VERSION ""

NS_ :

BS_:

BU_: Tester EMS
VAL_TABLE_ FMI 31 "Not available" 19 "Received network data in error" 18 "Below normal (moderately severe)" 17 "Below normal (least severe)" 16 "Above normal (moderately severe)" 15 "Above normal (least severe)" 14 "Special intstructions" 13 "Out of calibration" 12 "Bad intelligent device" 11 "Root cause not known" 10 "Abnormal rate of change" 9 "Abnormal update rate" 8 "Abnormal frequency" 7 "Mechanical system not responding" 6 "Current above normal" 5 "Current below normal" 4 "Voltage below normal" 3 "Voltage above normal" 2 "Data erratic" 1 "Below normal (most severe)" 0 "Above normal (most severe)" ;

BO_ 3221225472 VECTOR__INDEPENDENT_SIG_MSG: 0 Vector__XXX
 SG_ SPN5 : 0|16@1+ (1,0) [0|65536] "" Vector__XXX
 SG_ SPN4 : 0|16@1+ (1,0) [0|65536] "" Vector__XXX
 SG_ SPN3 : 0|16@1+ (1,0) [0|65536] "" Vector__XXX
 SG_ SPN2 : 0|16@1+ (1,0) [0|65536] "" Vector__XXX
 SG_ FailureModeIdentifier5 : 0|5@1+ (1,0) [0|0] "" Vector__XXX
 SG_ FailureModeIdentifier4 : 0|5@1+ (1,0) [0|0] "" Vector__XXX
 SG_ FlashRedStopLamp : 0|2@1+ (1,0) [0|3] "" Vector__XXX
 SG_ FlashProtectLamp : 0|2@1+ (1,0) [0|3] "" Vector__XXX
 SG_ FlashMalfuncIndicatorLamp : 0|2@1+ (1,0) [0|3] "" Vector__XXX
 SG_ FlashAmberWarningLamp : 0|2@1+ (1,0) [0|3] "" Vector__XXX
 SG_ FailureModeIdentifier3 : 0|5@1+ (1,0) [0|0] "" Vector__XXX
 SG_ FailureModeIdentifier2 : 0|5@1+ (1,0) [0|0] "" Vector__XXX
 SG_ SPNConversionMethod5 : 0|1@1+ (1,0) [0|1] "" Vector__XXX
 SG_ SPNConversionMethod4 : 0|1@1+ (1,0) [0|1] "" Vector__XXX
 SG_ SPNConversionMethod3 : 0|1@1+ (1,0) [0|1] "" Vector__XXX
 SG_ SPNConversionMethod2 : 0|1@1+ (1,0) [0|1] "" Vector__XXX
 SG_ OccurenceCount5 : 0|7@1+ (1,0) [0|126] "" Vector__XXX
 SG_ OccurenceCount4 : 0|7@1+ (1,0) [0|126] "" Vector__XXX
 SG_ OccurenceCount3 : 0|7@1+ (1,0) [0|126] "" Vector__XXX
 SG_ OccurenceCount2 : 0|7@1+ (1,0) [0|126] "" Vector__XXX
 SG_ OccurenceCount1 : 0|7@1+ (1,0) [0|126] "" Vector__XXX
 SG_ SPNConversionMethod1 : 0|1@1+ (1,0) [0|1] "" Vector__XXX
 SG_ FailureModeIdentifier1 : 0|5@1+ (1,0) [0|0] "" Vector__XXX
 SG_ SPN1 : 0|16@1+ (1,0) [0|65536] "" Vector__XXX
 SG_ MalfunctionIndicatorLampStatus : 0|2@1+ (1,0) [0|3] "" Vector__XXX
 SG_ RedStopLampState : 0|2@1+ (1,0) [0|3] "" Vector__XXX
 SG_ AmberWarningLampStatus : 0|2@1+ (1,0) [0|3] "" Vector__XXX
 SG_ ProtectLampStatus : 0|2@1+ (1,0) [0|3] "" Vector__XXX
 SG_ SPN5High : 0|3@1+ (1,0) [0|7] "" Vector__XXX
 SG_ SPN4High : 0|3@1+ (1,0) [0|7] "" Vector__XXX
 SG_ SPN3High : 0|3@1+ (1,0) [0|7] "" Vector__XXX
 SG_ SPN2High : 0|3@1+ (1,0) [0|7] "" Vector__XXX
 SG_ SPN1High : 0|3@1+ (1,0) [0|7] "" Vector__XXX
 SG_ OccurenceCount1 : 0|7@1+ (1,0) [0|126] "" Vector__XXX
 SG_ SPNConversionMethod1 : 0|1@1+ (1,0) [0|1] "" Vector__XXX
 SG_ FailureModeIdentifier1 : 0|5@1+ (1,0) [0|0] "" Vector__XXX
 SG_ SPN1 : 0|16@1+ (1,0) [0|65536] "" Vector__XXX
 SG_ SPN1High : 0|3@1+ (1,0) [0|7] "" Vector__XXX
 SG_ OccurenceCount1 : 0|7@1+ (1,0) [0|126] "" Vector__XXX
 SG_ SPNConversionMethod1 : 0|1@1+ (1,0) [0|1] "" Vector__XXX
 SG_ FailureModeIdentifier1 : 0|5@1+ (1,0) [0|0] "" Vector__XXX
 SG_ SPN1 : 0|16@1+ (1,0) [0|65536] "" Vector__XXX
 SG_ SPN1High : 0|3@1+ (1,0) [0|7] "" Vector__XXX
 SG_ SPN5 : 0|16@1+ (1,0) [0|65536] "" Vector__XXX
 SG_ SPN4 : 0|16@1+ (1,0) [0|65536] "" Vector__XXX
 SG_ SPN3 : 0|16@1+ (1,0) [0|65536] "" Vector__XXX
 SG_ SPN2 : 0|16@1+ (1,0) [0|65536] "" Vector__XXX
 SG_ FailureModeIdentifier5 : 0|5@1+ (1,0) [0|0] "" Vector__XXX
 SG_ FailureModeIdentifier4 : 0|5@1+ (1,0) [0|0] "" Vector__XXX
 SG_ OccurenceCount1 : 0|7@1+ (1,0) [0|126] "" Vector__XXX
 SG_ SPNConversionMethod1 : 0|1@1+ (1,0) [0|1] "" Vector__XXX
 SG_ FailureModeIdentifier1 : 0|5@1+ (1,0) [0|0] "" Vector__XXX
 SG_ SPN1 : 0|16@1+ (1,0) [0|65536] "" Vector__XXX
 SG_ MalfunctionIndicatorLampStatus : 0|2@1+ (1,0) [0|3] "" Vector__XXX
 SG_ RedStopLampState : 0|2@1+ (1,0) [0|3] "" Vector__XXX
 SG_ AmberWarningLampStatus : 0|2@1+ (1,0) [0|3] "" Vector__XXX
 SG_ ProtectLampStatus : 0|2@1+ (1,0) [0|3] "" Vector__XXX
 SG_ FailureModeIdentifier3 : 0|5@1+ (1,0) [0|0] "" Vector__XXX
 SG_ FlashRedStopLamp : 0|2@1+ (1,0) [0|3] "" Vector__XXX
 SG_ FlashProtectLamp : 0|2@1+ (1,0) [0|3] "" Vector__XXX
 SG_ FlashMalfuncIndicatorLamp : 0|2@1+ (1,0) [0|3] "" Vector__XXX
 SG_ FlashAmberWarningLamp : 0|2@1+ (1,0) [0|3] "" Vector__XXX
 SG_ FailureModeIdentifier2 : 0|5@1+ (1,0) [0|0] "" Vector__XXX
 SG_ SPNConversionMethod5 : 0|1@1+ (1,0) [0|1] "" Vector__XXX
 SG_ SPNConversionMethod4 : 0|1@1+ (1,0) [0|1] "" Vector__XXX
 SG_ SPNConversionMethod3 : 0|1@1+ (1,0) [0|1] "" Vector__XXX
 SG_ SPNConversionMethod2 : 0|1@1+ (1,0) [0|1] "" Vector__XXX
 SG_ OccurenceCount5 : 0|7@1+ (1,0) [0|126] "" Vector__XXX
 SG_ OccurenceCount4 : 0|7@1+ (1,0) [0|126] "" Vector__XXX
 SG_ OccurenceCount3 : 0|7@1+ (1,0) [0|126] "" Vector__XXX
 SG_ OccurenceCount2 : 0|7@1+ (1,0) [0|126] "" Vector__XXX
 SG_ SPN5High : 0|3@1+ (1,0) [0|7] "" Vector__XXX
 SG_ SPN4High : 0|3@1+ (1,0) [0|7] "" Vector__XXX
 SG_ SPN3High : 0|3@1+ (1,0) [0|7] "" Vector__XXX
 SG_ SPN2High : 0|3@1+ (1,0) [0|7] "" Vector__XXX
 SG_ SPN1High : 0|3@1+ (1,0) [0|7] "" Vector__XXX
 SG_ SPN5 : 0|16@1+ (1,0) [0|65536] "" Vector__XXX
 SG_ SPN4 : 0|16@1+ (1,0) [0|65536] "" Vector__XXX
 SG_ SPN3 : 0|16@1+ (1,0) [0|65536] "" Vector__XXX
 SG_ SPN2 : 0|16@1+ (1,0) [0|65536] "" Vector__XXX
 SG_ FlashRedStopLamp : 0|2@1+ (1,0) [0|3] "" Vector__XXX
 SG_ FlashProtectLamp : 0|2@1+ (1,0) [0|3] "" Vector__XXX
 SG_ FailureModeIdentifier5 : 0|5@1+ (1,0) [0|0] "" Vector__XXX
 SG_ FailureModeIdentifier4 : 0|5@1+ (1,0) [0|0] "" Vector__XXX
 SG_ FailureModeIdentifier3 : 0|5@1+ (1,0) [0|0] "" Vector__XXX
 SG_ OccurenceCount1 : 0|7@1+ (1,0) [0|126] "" Vector__XXX
 SG_ SPNConversionMethod1 : 0|1@1+ (1,0) [0|1] "" Vector__XXX
 SG_ FailureModeIdentifier1 : 0|5@1+ (1,0) [0|0] "" Vector__XXX
 SG_ SPN1 : 0|16@1+ (1,0) [0|65536] "" Vector__XXX
 SG_ MalfunctionIndicatorLampStatus : 0|2@1+ (1,0) [0|3] "" Vector__XXX
 SG_ RedStopLampState : 0|2@1+ (1,0) [0|3] "" Vector__XXX
 SG_ AmberWarningLampStatus : 0|2@1+ (1,0) [0|3] "" Vector__XXX
 SG_ ProtectLampStatus : 0|2@1+ (1,0) [0|3] "" Vector__XXX
 SG_ FlashMalfuncIndicatorLamp : 0|2@1+ (1,0) [0|3] "" Vector__XXX
 SG_ FlashAmberWarningLamp : 0|2@1+ (1,0) [0|3] "" Vector__XXX
 SG_ FailureModeIdentifier2 : 0|5@1+ (1,0) [0|0] "" Vector__XXX
 SG_ SPNConversionMethod5 : 0|1@1+ (1,0) [0|1] "" Vector__XXX
 SG_ SPNConversionMethod4 : 0|1@1+ (1,0) [0|1] "" Vector__XXX
 SG_ SPNConversionMethod3 : 0|1@1+ (1,0) [0|1] "" Vector__XXX
 SG_ SPNConversionMethod2 : 0|1@1+ (1,0) [0|1] "" Vector__XXX
 SG_ OccurenceCount5 : 0|7@1+ (1,0) [0|126] "" Vector__XXX
 SG_ OccurenceCount4 : 0|7@1+ (1,0) [0|126] "" Vector__XXX
 SG_ OccurenceCount3 : 0|7@1+ (1,0) [0|126] "" Vector__XXX
 SG_ OccurenceCount2 : 0|7@1+ (1,0) [0|126] "" Vector__XXX
 SG_ SPN5High : 0|3@1+ (1,0) [0|7] "" Vector__XXX
 SG_ SPN4High : 0|3@1+ (1,0) [0|7] "" Vector__XXX
 SG_ SPN3High : 0|3@1+ (1,0) [0|7] "" Vector__XXX
 SG_ SPN2High : 0|3@1+ (1,0) [0|7] "" Vector__XXX
 SG_ SPN1High : 0|3@1+ (1,0) [0|7] "" Vector__XXX
 SG_ SPN5 : 0|16@1+ (1,0) [0|65536] "" Vector__XXX
 SG_ SPN4 : 0|16@1+ (1,0) [0|65536] "" Vector__XXX
 SG_ SPN3 : 0|16@1+ (1,0) [0|65536] "" Vector__XXX
 SG_ SPN2 : 0|16@1+ (1,0) [0|65536] "" Vector__XXX
 SG_ FailureModeIdentifier5 : 0|5@1+ (1,0) [0|0] "" Vector__XXX
 SG_ FailureModeIdentifier4 : 0|5@1+ (1,0) [0|0] "" Vector__XXX
 SG_ FailureModeIdentifier3 : 0|5@1+ (1,0) [0|0] "" Vector__XXX
 SG_ OccurenceCount1 : 0|7@1+ (1,0) [0|126] "" Vector__XXX
 SG_ SPNConversionMethod1 : 0|1@1+ (1,0) [0|1] "" Vector__XXX
 SG_ FailureModeIdentifier1 : 0|5@1+ (1,0) [0|0] "" Vector__XXX
 SG_ SPN1 : 0|16@1+ (1,0) [0|65536] "" Vector__XXX
 SG_ FailureModeIdentifier2 : 0|5@1+ (1,0) [0|0] "" Vector__XXX
 SG_ SPNConversionMethod5 : 0|1@1+ (1,0) [0|1] "" Vector__XXX
 SG_ SPNConversionMethod4 : 0|1@1+ (1,0) [0|1] "" Vector__XXX
 SG_ SPNConversionMethod3 : 0|1@1+ (1,0) [0|1] "" Vector__XXX
 SG_ SPNConversionMethod2 : 0|1@1+ (1,0) [0|1] "" Vector__XXX
 SG_ OccurenceCount5 : 0|7@1+ (1,0) [0|126] "" Vector__XXX
 SG_ OccurenceCount4 : 0|7@1+ (1,0) [0|126] "" Vector__XXX
 SG_ OccurenceCount3 : 0|7@1+ (1,0) [0|126] "" Vector__XXX
 SG_ OccurenceCount2 : 0|7@1+ (1,0) [0|126] "" Vector__XXX
 SG_ SPN5High : 0|3@1+ (1,0) [0|7] "" Vector__XXX
 SG_ SPN4High : 0|3@1+ (1,0) [0|7] "" Vector__XXX
 SG_ SPN3High : 0|3@1+ (1,0) [0|7] "" Vector__XXX
 SG_ SPN2High : 0|3@1+ (1,0) [0|7] "" Vector__XXX
 SG_ SPN1High : 0|3@1+ (1,0) [0|7] "" Vector__XXX

BO_ 2566843646 VI: 8 Vector__XXX

BO_ 2566832638 VDHR: 8 Vector__XXX
 SG_ HighResolutionTripDistance : 32|32@1+ (0.005,0) [0|21055406] "km" Vector__XXX
 SG_ HghRslutionTotalVehicleDistance : 0|32@1+ (0.005,0) [0|21055406] "km" Vector__XXX

BO_ 2566840574 VD: 8 Vector__XXX
 SG_ TotalVehicleDistance : 32|32@1+ (0.125,0) [0|526385151.9] "km" Vector__XXX
 SG_ TripDistance : 0|32@1+ (0.125,0) [0|526385151.9] "km" Vector__XXX

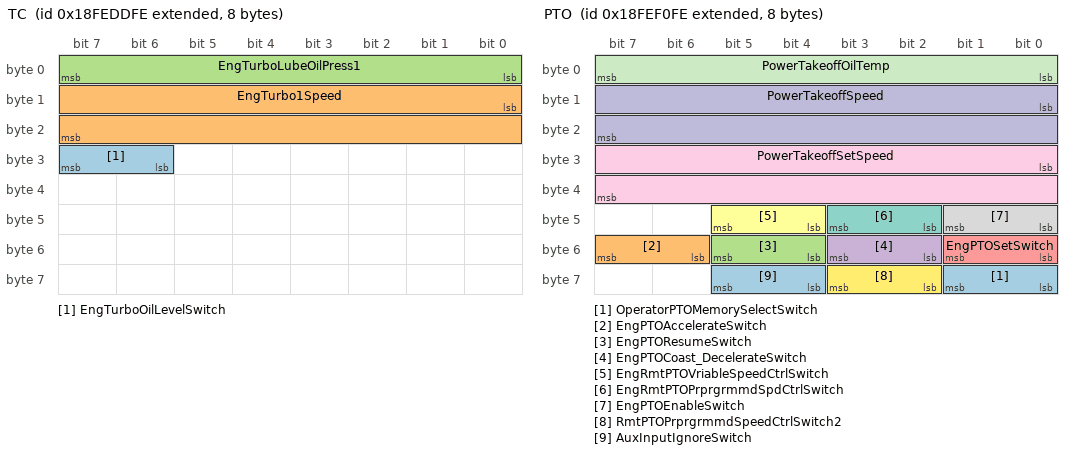
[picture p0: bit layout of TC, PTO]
BO_ 2566839806 TC: 8 Vector__XXX
 SG_ EngTurboOilLevelSwitch : 30|2@1+ (1,0) [0|3] "" Vector__XXX
 SG_ EngTurbo1Speed : 8|16@1+ (4,0) [0|257020] "RPM" Vector__XXX
 SG_ EngTurboLubeOilPress1 : 0|8@1+ (4,0) [0|1000] "kPa" Vector__XXX

BO_ 2566841598 SHUTDOW: 8 Vector__XXX
 SG_ EngOverspeedTest : 54|2@1+ (1,0) [0|3] "" Vector__XXX
 SG_ EngAirShutoffCmdStatus : 52|2@1+ (1,0) [0|3] "" Vector__XXX
 SG_ EngAlarmOutputCmdStatus : 50|2@1+ (1,0) [0|3] "" Vector__XXX
 SG_ EngAlarmAcknowledge : 48|2@1+ (1,0) [0|3] "" Vector__XXX
 SG_ EngProtectionSystemConfig : 46|2@1+ (1,0) [0|3] "" Vector__XXX
 SG_ EngProtectionSystemTimerState : 38|2@1+ (1,0) [0|3] "" Vector__XXX
 SG_ EngPrtectionSystemTimerOverride : 36|2@1+ (1,0) [0|3] "" Vector__XXX
 SG_ EngPrtctnSystmApprchingShutdown : 34|2@1+ (1,0) [0|3] "" Vector__XXX
 SG_ EngPrtctionSystemHasShutdownEng : 32|2@1+ (1,0) [0|3] "" Vector__XXX
 SG_ EngWaitToStartLamp : 24|2@1+ (1,0) [0|3] "" Vector__XXX
 SG_ RefrigerantHighPressSwitch : 20|2@1+ (1,0) [0|3] "" Vector__XXX
 SG_ RefrigerantLowPressSwitch : 18|2@1+ (1,0) [0|3] "" Vector__XXX
 SG_ A_CHighPressFanSwitch : 16|2@1+ (1,0) [0|3] "" Vector__XXX
 SG_ EngIdleShutdownTimerFunction : 14|2@1+ (1,0) [0|3] "" Vector__XXX
 SG_ EngIdleShutdownTimerState : 6|2@1+ (1,0) [0|3] "" Vector__XXX
 SG_ EngIdleShutdownTimerOverride : 4|2@1+ (1,0) [0|3] "" Vector__XXX
 SG_ EngIdleShutdownDriverAlertMode : 2|2@1+ (1,0) [0|3] "" Vector__XXX
 SG_ EngIdleShutdownHasShutdownEng : 0|2@1+ (1,0) [0|3] "" Vector__XXX

BO_ 2566844670 PTO: 8 Vector__XXX
 SG_ OperatorPTOMemorySelectSwitch : 56|2@1+ (1,0) [0|3] "" Vector__XXX
 SG_ EngPTOAccelerateSwitch : 54|2@1+ (1,0) [0|3] "" Vector__XXX
 SG_ EngPTOResumeSwitch : 52|2@1+ (1,0) [0|3] "" Vector__XXX
 SG_ EngPTOCoast_DecelerateSwitch : 50|2@1+ (1,0) [0|3] "" Vector__XXX
 SG_ EngPTOSetSwitch : 48|2@1+ (1,0) [0|3] "" Vector__XXX
 SG_ EngRmtPTOVriableSpeedCtrlSwitch : 44|2@1+ (1,0) [0|3] "" Vector__XXX
 SG_ EngRmtPTOPrprgrmmdSpdCtrlSwitch : 42|2@1+ (1,0) [0|3] "" Vector__XXX
 SG_ EngPTOEnableSwitch : 40|2@1+ (1,0) [0|3] "" Vector__XXX
 SG_ PowerTakeoffSetSpeed : 24|16@1+ (0.125,0) [0|8031.875] "RPM" Vector__XXX
 SG_ PowerTakeoffSpeed : 8|16@1+ (0.125,0) [0|8031.875] "RPM" Vector__XXX
 SG_ PowerTakeoffOilTemp : 0|8@1+ (1,-40) [-40|210] "°C" Vector__XXX
 SG_ RmtPTOPrprgrmmdSpeedCtrlSwitch2 : 58|2@1+ (1,0) [0|3] "" Vector__XXX
 SG_ AuxInputIgnoreSwitch : 60|2@1+ (1,0) [0|3] "" Vector__XXX

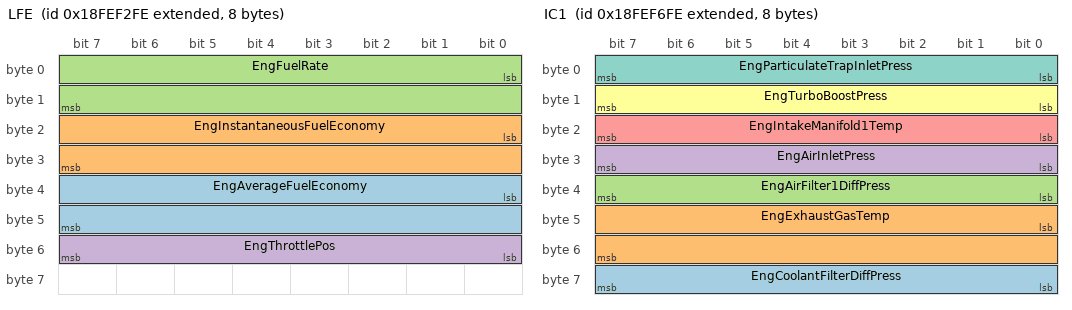
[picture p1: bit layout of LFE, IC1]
BO_ 2566845182 LFE: 8 Vector__XXX
 SG_ EngAverageFuelEconomy : 32|16@1+ (0.001953125,0) [0|125.5] "km/L" Vector__XXX
 SG_ EngInstantaneousFuelEconomy : 16|16@1+ (0.001953125,0) [0|125.5] "km/L" Vector__XXX
 SG_ EngFuelRate : 0|16@1+ (0.05,0) [0|3212.75] "L/hr" Vector__XXX
 SG_ EngThrottlePos : 48|8@1+ (0.4,0) [0|100] "%" Vector__XXX

BO_ 2566842878 LFC: 8 Vector__XXX
 SG_ EngTotalFuelUsed : 32|32@1+ (0.5,0) [0|2105540607.5] "L" Vector__XXX
 SG_ EngTripFuel : 0|32@1+ (0.5,0) [0|2105540607.5] "L" Vector__XXX

BO_ 2566846206 IC1: 8 Vector__XXX
 SG_ EngCoolantFilterDiffPress : 56|8@1+ (0.5,0) [0|125] "kPa" Vector__XXX
 SG_ EngExhaustGasTemp : 40|16@1+ (0.03125,-273) [-273|1735] "°C" Vector__XXX
 SG_ EngAirFilter1DiffPress : 32|8@1+ (0.05,0) [0|12.5] "kPa" Vector__XXX
 SG_ EngAirInletPress : 24|8@1+ (2,0) [0|500] "kPa" Vector__XXX
 SG_ EngIntakeManifold1Temp : 16|8@1+ (1,-40) [-40|210] "°C" Vector__XXX
 SG_ EngTurboBoostPress : 8|8@1+ (2,0) [0|500] "kPa" Vector__XXX
 SG_ EngParticulateTrapInletPress : 0|8@1+ (0.5,0) [0|125] "kPa" Vector__XXX

BO_ 2566841854 HOURS: 8 Vector__XXX
 SG_ EngTotalRevolutions : 32|32@1+ (1000,0) [0|4211081215000] "rev" Vector__XXX
 SG_ EngTotalHoursOfOperation : 0|32@1+ (0.05,0) [0|210554060.75] "hr" Vector__XXX

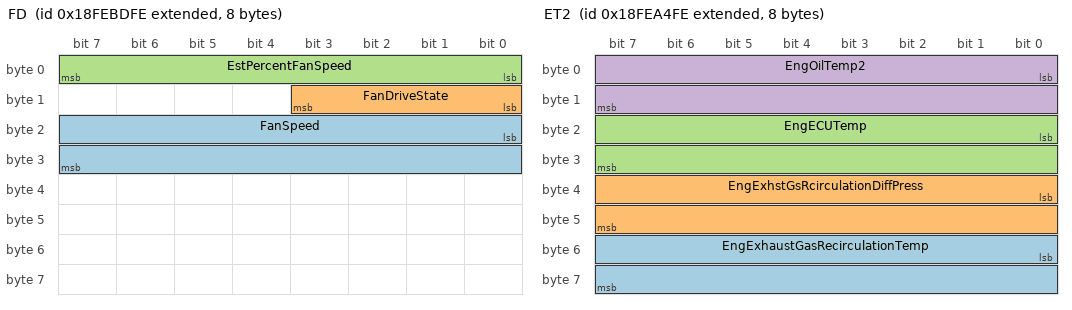
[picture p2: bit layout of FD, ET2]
BO_ 2566831614 FD: 8 Vector__XXX
 SG_ FanSpeed : 16|16@1+ (0.125,0) [0|8031.875] "RPM" Vector__XXX
 SG_ FanDriveState : 8|4@1+ (1,0) [0|15] "" Vector__XXX
 SG_ EstPercentFanSpeed : 0|8@1+ (0.4,0) [0|100] "%" Vector__XXX

BO_ 2566825214 ET2: 8 Vector__XXX
 SG_ EngExhaustGasRecirculationTemp : 48|16@1+ (0.03125,-273) [-273|1735] "°C" Vector__XXX
 SG_ EngExhstGsRcirculationDiffPress : 32|16@1+ (0.0078125,-250) [-250|251.99] "kPa" Vector__XXX
 SG_ EngECUTemp : 16|16@1+ (0.03125,-273) [-273|1735] "°C" Vector__XXX
 SG_ EngOilTemp2 : 0|16@1+ (0.03125,-273) [-273|1735] "°C" Vector__XXX

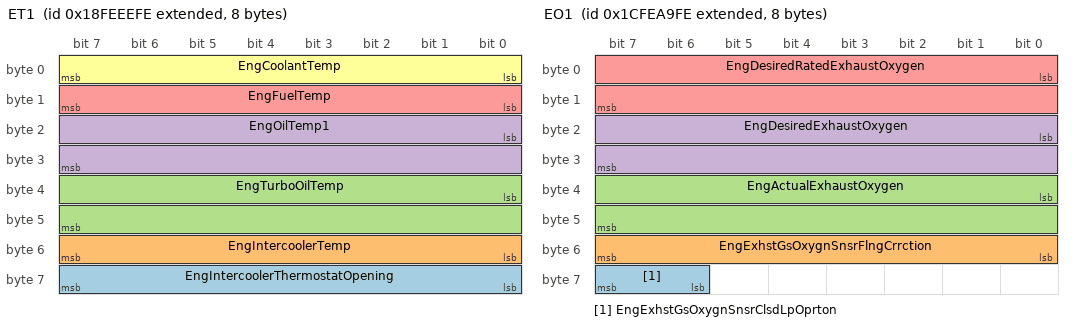
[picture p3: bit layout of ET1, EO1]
BO_ 2566844158 ET1: 8 Vector__XXX
 SG_ EngIntercoolerThermostatOpening : 56|8@1+ (0.4,0) [0|100] "%" Vector__XXX
 SG_ EngIntercoolerTemp : 48|8@1+ (1,-40) [-40|210] "°C" Vector__XXX
 SG_ EngTurboOilTemp : 32|16@1+ (0.03125,-273) [-273|1735] "°C" Vector__XXX
 SG_ EngOilTemp1 : 16|16@1+ (0.03125,-273) [-273|1735] "°C" Vector__XXX
 SG_ EngFuelTemp : 8|8@1+ (1,-40) [-40|210] "°C" Vector__XXX
 SG_ EngCoolantTemp : 0|8@1+ (1,-40) [-40|210] "°C" Vector__XXX

BO_ 2633935358 EO1: 8 Vector__XXX
 SG_ EngExhstGsOxygnSnsrClsdLpOprton : 62|2@1+ (1,0) [0|3] "" Vector__XXX
 SG_ EngExhstGsOxygnSnsrFlngCrrction : 48|8@1+ (1,-125) [-125|125] "%" Vector__XXX
 SG_ EngActualExhaustOxygen : 32|16@1+ (0.0025,0) [0|160.6375] "%" Vector__XXX
 SG_ EngDesiredExhaustOxygen : 16|16@1+ (0.0025,0) [0|160.6375] "%" Vector__XXX
 SG_ EngDesiredRatedExhaustOxygen : 0|16@1+ (0.0025,0) [0|160.6375] "%" Vector__XXX

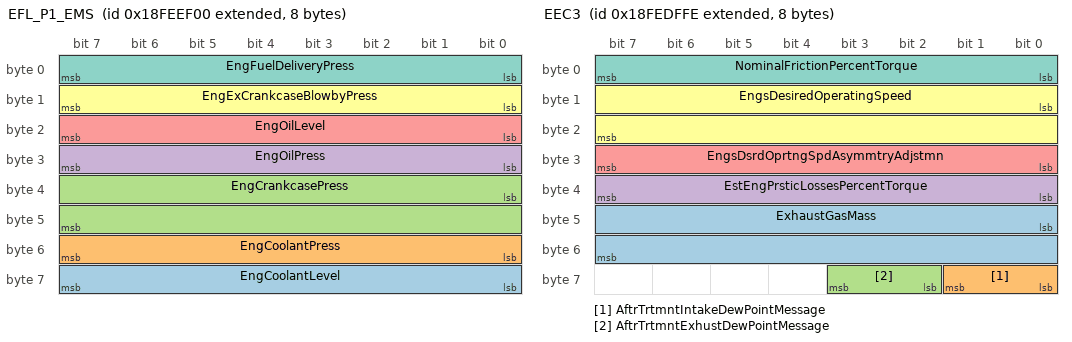
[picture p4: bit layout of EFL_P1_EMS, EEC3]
BO_ 2566844160 EFL_P1_EMS: 8 Vector__XXX
 SG_ EngCoolantLevel : 56|8@1+ (0.4,0) [0|100] "%" Vector__XXX
 SG_ EngCoolantPress : 48|8@1+ (2,0) [0|500] "kPa" Vector__XXX
 SG_ EngCrankcasePress : 32|16@1+ (0.0078125,-250) [-250|251.99] "kPa" Vector__XXX
 SG_ EngOilPress : 24|8@1+ (4,0) [0|1000] "kPa" Vector__XXX
 SG_ EngOilLevel : 16|8@1+ (0.4,0) [0|100] "%" Vector__XXX
 SG_ EngExCrankcaseBlowbyPress : 8|8@1+ (0.05,0) [0|12.5] "kPa" Vector__XXX
 SG_ EngFuelDeliveryPress : 0|8@1+ (4,0) [0|1000] "kPa" Vector__XXX

BO_ 2566840318 EEC3: 8 Vector__XXX
 SG_ ExhaustGasMass : 40|16@1+ (2,0) [0|128510] "kg" Vector__XXX
 SG_ AftrTrtmntIntakeDewPointMessage : 56|2@1+ (1,0) [0|3] "" Vector__XXX
 SG_ AftrTrtmntExhustDewPointMessage : 58|2@1+ (1,0) [0|3] "" Vector__XXX
 SG_ EstEngPrsticLossesPercentTorque : 32|8@1+ (1,-125) [-125|125] "%" Vector__XXX
 SG_ EngsDsrdOprtngSpdAsymmtryAdjstmn : 24|8@1+ (1,0) [0|250] "" Vector__XXX
 SG_ EngsDesiredOperatingSpeed : 8|16@1+ (0.125,0) [0|8031.875] "RPM" Vector__XXX
 SG_ NominalFrictionPercentTorque : 0|8@1+ (1,-125) [-125|125] "%" Vector__XXX

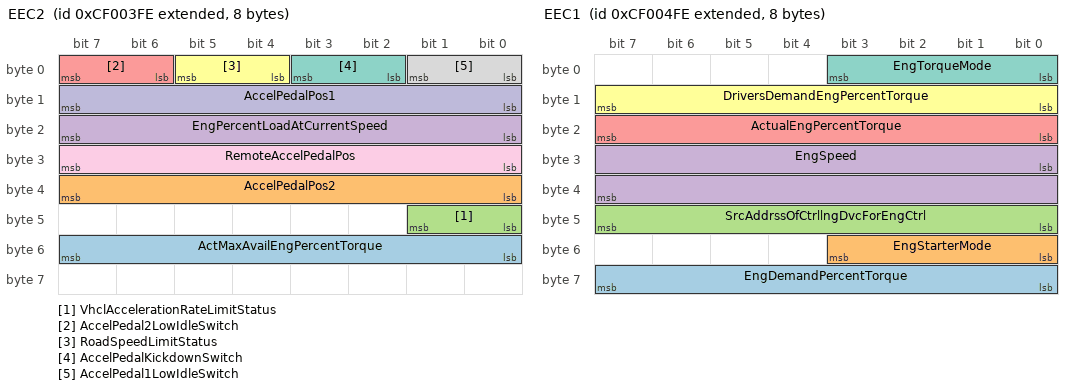
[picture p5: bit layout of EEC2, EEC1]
BO_ 2364539902 EEC2: 8 Vector__XXX
 SG_ ActMaxAvailEngPercentTorque : 48|8@1+ (0.4,0) [0|100] "%" Vector__XXX
 SG_ AccelPedalPos2 : 32|8@1+ (0.4,0) [0|100] "%" Vector__XXX
 SG_ VhclAccelerationRateLimitStatus : 40|2@1+ (1,0) [0|3] "" Vector__XXX
 SG_ EngPercentLoadAtCurrentSpeed : 16|8@1+ (1,0) [0|250] "%" Vector__XXX
 SG_ AccelPedal2LowIdleSwitch : 6|2@1+ (1,0) [0|3] "" Vector__XXX
 SG_ RoadSpeedLimitStatus : 4|2@1+ (1,0) [0|3] "" Vector__XXX
 SG_ AccelPedalKickdownSwitch : 2|2@1+ (1,0) [0|3] "" Vector__XXX
 SG_ AccelPedal1LowIdleSwitch : 0|2@1+ (1,0) [0|3] "" Vector__XXX
 SG_ RemoteAccelPedalPos : 24|8@1+ (0.4,0) [0|100] "%" Vector__XXX
 SG_ AccelPedalPos1 : 8|8@1+ (0.4,0) [0|100] "%" Vector__XXX

BO_ 2364540158 EEC1: 8 Vector__XXX
 SG_ EngDemandPercentTorque : 56|8@1+ (1,-125) [-125|125] "%" Vector__XXX
 SG_ EngStarterMode : 48|4@1+ (1,0) [0|15] "" Vector__XXX
 SG_ SrcAddrssOfCtrllngDvcForEngCtrl : 40|8@1+ (1,0) [0|255] "" Vector__XXX
 SG_ EngSpeed : 24|16@1+ (0.125,0) [0|8031.875] "rpm" Vector__XXX
 SG_ ActualEngPercentTorque : 16|8@1+ (1,-125) [-125|125] "%" Vector__XXX
 SG_ DriversDemandEngPercentTorque : 8|8@1+ (1,-125) [-125|125] "%" Vector__XXX
 SG_ EngTorqueMode : 0|4@1+ (1,0) [0|15] "" Vector__XXX

BO_ 2566841342 EC: 39 Vector__XXX
 SG_ SupportTSC1CtrlPurposeGroup4Of4 : 304|8@1+ (1,0) [0|255] "" Vector__XXX
 SG_ SupportVariableRateTSC1Message : 272|8@1+ (1,0) [0|255] "" Vector__XXX
 SG_ SupportTSC1CtrlPurposeGroup3Of4 : 296|8@1+ (1,0) [0|255] "" Vector__XXX
 SG_ SupportTSC1CtrlPurposeGroup2Of4 : 288|8@1+ (1,0) [0|255] "" Vector__XXX
 SG_ SupportTSC1CtrlPurposeGroup1Of4 : 280|8@1+ (1,0) [0|255] "" Vector__XXX
 SG_ EngDefaultTorqueLimit : 256|16@1+ (1,0) [0|64255] "Nm" Vector__XXX
 SG_ EngMomentOfInertia : 240|16@1+ (0.004,0) [0|257.02] "kg-m²" Vector__XXX
 SG_ EngExRngRqdSpdCtrlRngUpperLimit : 224|16@1+ (0.125,0) [0|8031.875] "RPM" Vector__XXX
 SG_ EngRqdTorqueCtrlRangeUpperLimit : 216|8@1+ (1,-125) [-125|125] "%" Vector__XXX
 SG_ EngRqdTorqueCtrlRangeLowerLimit : 208|8@1+ (1,-125) [-125|125] "%" Vector__XXX
 SG_ EngRqedSpeedCtrlRangeUpperLimit : 200|8@1+ (10,0) [0|2500] "RPM" Vector__XXX
 SG_ EngRqedSpeedCtrlRangeLowerLimit : 192|8@1+ (10,0) [0|2500] "RPM" Vector__XXX
 SG_ EngMxMomentaryOverrideTimeLimit : 184|8@1+ (0.1,0) [0|25] "sec" Vector__XXX
 SG_ EngMxMmntaryOverrideSpeedPoint7 : 168|16@1+ (0.125,0) [0|8031.875] "RPM" Vector__XXX
 SG_ EngReferenceTorque : 152|16@1+ (1,0) [0|64255] "Nm" Vector__XXX
 SG_ EngSpeedAtHighIdlePoint6 : 120|16@1+ (0.125,0) [0|8031.875] "RPM" Vector__XXX
 SG_ EngGainOfEndspeedGovernor : 136|16@1+ (0.00078125,0) [0|50.2] "%/rpm" Vector__XXX
 SG_ EngPercentTorqueAtPoint5 : 112|8@1+ (1,-125) [-125|125] "%" Vector__XXX
 SG_ EngSpeedAtPoint5 : 96|16@1+ (0.125,0) [0|8031.875] "RPM" Vector__XXX
 SG_ EngPercentTorqueAtPoint4 : 88|8@1+ (1,-125) [-125|125] "%" Vector__XXX
 SG_ EngSpeedAtPoint4 : 72|16@1+ (0.125,0) [0|8031.875] "RPM" Vector__XXX
 SG_ EngPercentTorqueAtPoint3 : 64|8@1+ (1,-125) [-125|125] "%" Vector__XXX
 SG_ EngSpeedAtPoint3 : 48|16@1+ (0.125,0) [0|8031.875] "RPM" Vector__XXX
 SG_ EngPercentTorqueAtPoint2 : 40|8@1+ (1,-125) [-125|125] "%" Vector__XXX
 SG_ EngSpeedAtPoint2 : 24|16@1+ (0.125,0) [0|8031.875] "RPM" Vector__XXX
 SG_ EngPercentTorqueAtIdlePoint1 : 16|8@1+ (1,-125) [-125|125] "%" Vector__XXX
 SG_ EngSpeedAtIdlePoint1 : 0|16@1+ (0.125,0) [0|8031.875] "RPM" Vector__XXX

BO_ 2566844926 CCVS: 8 Vector__XXX
 SG_ EngShutdownOverrideSwitch : 62|2@1+ (1,0) [0|3] "" Vector__XXX
 SG_ EngTestModeSwitch : 60|2@1+ (1,0) [0|3] "" Vector__XXX
 SG_ EngIdleDecrementSwitch : 58|2@1+ (1,0) [0|3] "" Vector__XXX
 SG_ EngIdleIncrementSwitch : 56|2@1+ (1,0) [0|3] "" Vector__XXX
 SG_ CruiseCtrlStates : 53|3@1+ (1,0) [0|7] "" Vector__XXX
 SG_ PTOState : 48|5@1+ (1,0) [0|31] "" Vector__XXX
 SG_ CruiseCtrlSetSpeed : 40|8@1+ (1,0) [0|250] "km/h" Vector__XXX
 SG_ CruiseCtrlAccelerateSwitch : 38|2@1+ (1,0) [0|3] "" Vector__XXX
 SG_ CruiseCtrlResumeSwitch : 36|2@1+ (1,0) [0|3] "" Vector__XXX
 SG_ CruiseCtrlCoastSwitch : 34|2@1+ (1,0) [0|3] "" Vector__XXX
 SG_ CruiseCtrlSetSwitch : 32|2@1+ (1,0) [0|3] "" Vector__XXX
 SG_ ClutchSwitch : 30|2@1+ (1,0) [0|3] "" Vector__XXX
 SG_ BrakeSwitch : 28|2@1+ (1,0) [0|3] "" Vector__XXX
 SG_ CruiseCtrlEnableSwitch : 26|2@1+ (1,0) [0|3] "" Vector__XXX
 SG_ CruiseCtrlActive : 24|2@1+ (1,0) [0|3] "" Vector__XXX
 SG_ WheelBasedVehicleSpeed : 8|16@1+ (0.00390625,0) [0|250.996] "km/h" Vector__XXX
 SG_ CruiseCtrlPauseSwitch : 4|2@1+ (1,0) [0|3] "" Vector__XXX
 SG_ ParkingBrakeSwitch : 2|2@1+ (1,0) [0|3] "" Vector__XXX
 SG_ TwoSpeedAxleSwitch : 0|2@1+ (1,0) [0|3] "" Vector__XXX

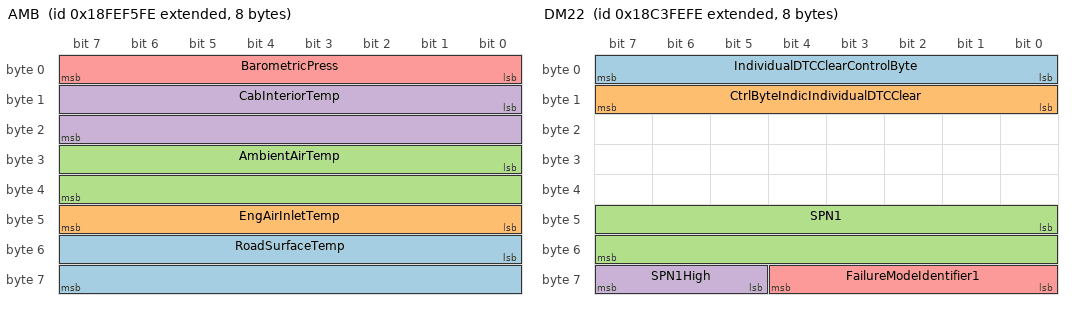
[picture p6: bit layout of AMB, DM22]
BO_ 2566845950 AMB: 8 Vector__XXX
 SG_ RoadSurfaceTemp : 48|16@1+ (0.03125,-273) [-273|1735] "°C" Vector__XXX
 SG_ EngAirInletTemp : 40|8@1+ (1,-40) [-40|210] "°C" Vector__XXX
 SG_ AmbientAirTemp : 24|16@1+ (0.03125,-273) [-273|1735] "°C" Vector__XXX
 SG_ CabInteriorTemp : 8|16@1+ (0.03125,-273) [-273|1735] "°C" Vector__XXX
 SG_ BarometricPress : 0|8@1+ (0.5,0) [0|125] "kPa" Vector__XXX

BO_ 2562981630 DM22: 8 Vector__XXX
 SG_ IndividualDTCClearControlByte : 0|8@1+ (1,0) [0|255] "" Vector__XXX
 SG_ CtrlByteIndicIndividualDTCClear : 8|8@1+ (1,0) [0|255] "" Vector__XXX
 SG_ SPN1 : 40|16@1+ (1,0) [0|65536] "" Vector__XXX
 SG_ SPN1High : 61|3@1+ (1,0) [0|7] "" Vector__XXX
 SG_ FailureModeIdentifier1 : 56|5@1+ (1,0) [0|0] "" Vector__XXX

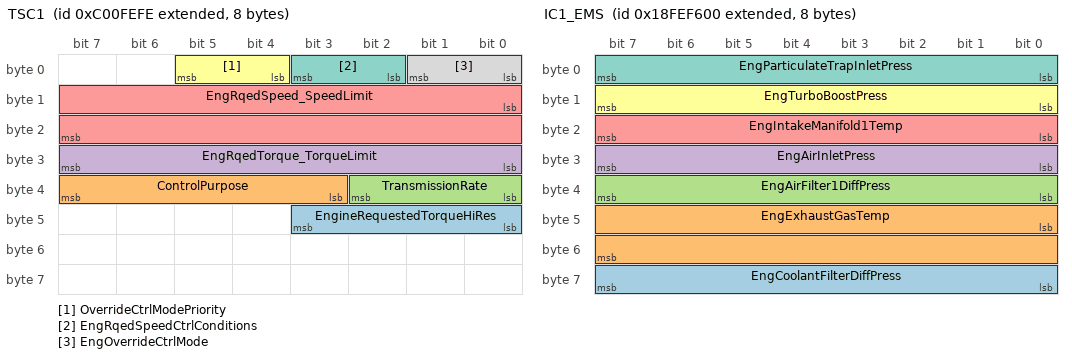
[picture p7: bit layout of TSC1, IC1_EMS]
BO_ 2348875518 TSC1: 8 Vector__XXX
 SG_ EngineRequestedTorqueHiRes : 40|4@1+ (0.125,0) [0|0.875] "%" Vector__XXX
 SG_ ControlPurpose : 35|5@1+ (1,0) [0|31] "" Vector__XXX
 SG_ TransmissionRate : 32|3@1+ (1,0) [0|7] "" Vector__XXX
 SG_ EngRqedTorque_TorqueLimit : 24|8@1+ (1,-125) [-125|125] "%" Vector__XXX
 SG_ EngRqedSpeed_SpeedLimit : 8|16@1+ (0.125,0) [0|8031.875] "RPM" Vector__XXX
 SG_ OverrideCtrlModePriority : 4|2@1+ (1,0) [0|3] "" Vector__XXX
 SG_ EngRqedSpeedCtrlConditions : 2|2@1+ (1,0) [0|3] "" Vector__XXX
 SG_ EngOverrideCtrlMode : 0|2@1+ (1,0) [0|3] "" Vector__XXX

BO_ 2566837246 DM11: 0 Vector__XXX

BO_ 2684354558 CAPL_MSG: 1785 Vector__XXX

BO_ 2566845952 IC1_EMS: 8 EMS
 SG_ EngCoolantFilterDiffPress : 56|8@1+ (0.5,0) [0|125] "kPa" Vector__XXX
 SG_ EngExhaustGasTemp : 40|16@1+ (0.03125,-273) [-273|1735] "°C" Vector__XXX
 SG_ EngAirFilter1DiffPress : 32|8@1+ (0.05,0) [0|12.5] "kPa" Vector__XXX
 SG_ EngAirInletPress : 24|8@1+ (2,0) [0|500] "kPa" Vector__XXX
 SG_ EngIntakeManifold1Temp : 16|8@1+ (1,-40) [-40|210] "°C" Vector__XXX
 SG_ EngTurboBoostPress : 8|8@1+ (2,0) [0|500] "kPa" Vector__XXX
 SG_ EngParticulateTrapInletPress : 0|8@1+ (0.5,0) [0|125] "kPa" Vector__XXX

BO_ 2566841600 HOURS_EMS: 8 EMS
 SG_ EngTotalRevolutions : 32|32@1+ (1000,0) [0|4211081215000] "rev" Vector__XXX
 SG_ EngTotalHoursOfOperation : 0|32@1+ (0.05,0) [0|210554060.75] "hr" Vector__XXX

BO_ 2566843392 VI_EMS: 8 EMS

BO_ 2566832384 VDHR_EMS: 8 EMS
 SG_ HighResolutionTripDistance : 32|32@1+ (0.005,0) [0|21055406] "km" Vector__XXX
 SG_ HghRslutionTotalVehicleDistance : 0|32@1+ (0.005,0) [0|21055406] "km" Vector__XXX

BO_ 2566840320 VD_EMS: 8 EMS
 SG_ TotalVehicleDistance : 32|32@1+ (0.125,0) [0|526385151.9] "km" Vector__XXX
 SG_ TripDistance : 0|32@1+ (0.125,0) [0|526385151.9] "km" Vector__XXX

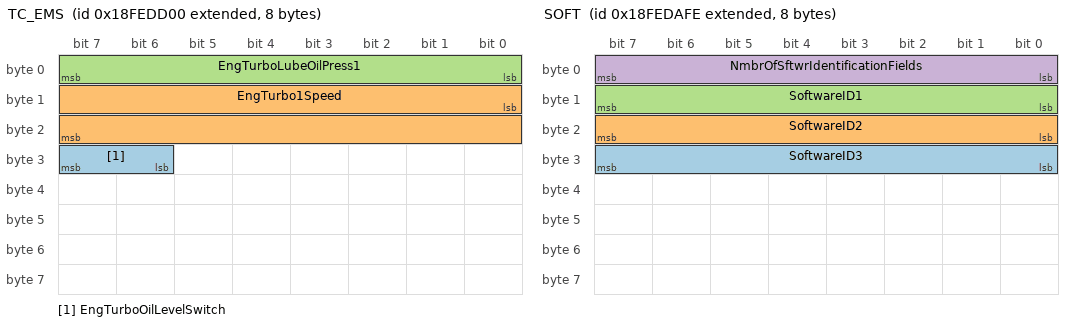
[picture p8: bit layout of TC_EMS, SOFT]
BO_ 2566839552 TC_EMS: 8 EMS
 SG_ EngTurboOilLevelSwitch : 30|2@1+ (1,0) [0|3] "" Vector__XXX
 SG_ EngTurbo1Speed : 8|16@1+ (4,0) [0|257020] "RPM" Vector__XXX
 SG_ EngTurboLubeOilPress1 : 0|8@1+ (4,0) [0|1000] "kPa" Vector__XXX

BO_ 2566839038 SOFT: 8 EMS
 SG_ SoftwareID3 : 24|8@1+ (1,0) [0|255] "" Vector__XXX
 SG_ SoftwareID2 : 16|8@1+ (1,0) [0|255] "" Vector__XXX
 SG_ SoftwareID1 : 8|8@1+ (1,0) [0|255] "" Vector__XXX
 SG_ NmbrOfSftwrIdentificationFields : 0|8@1+ (1,0) [0|250] "steps" Vector__XXX

BO_ 2566841344 SHUTDOW_EMS: 8 EMS
 SG_ EngOverspeedTest : 54|2@1+ (1,0) [0|3] "" Vector__XXX
 SG_ EngAirShutoffCmdStatus : 52|2@1+ (1,0) [0|3] "" Vector__XXX
 SG_ EngAlarmOutputCmdStatus : 50|2@1+ (1,0) [0|3] "" Vector__XXX
 SG_ EngAlarmAcknowledge : 48|2@1+ (1,0) [0|3] "" Vector__XXX
 SG_ EngProtectionSystemConfig : 46|2@1+ (1,0) [0|3] "" Vector__XXX
 SG_ EngProtectionSystemTimerState : 38|2@1+ (1,0) [0|3] "" Vector__XXX
 SG_ EngPrtectionSystemTimerOverride : 36|2@1+ (1,0) [0|3] "" Vector__XXX
 SG_ EngPrtctnSystmApprchingShutdown : 34|2@1+ (1,0) [0|3] "" Vector__XXX
 SG_ EngPrtctionSystemHasShutdownEng : 32|2@1+ (1,0) [0|3] "" Vector__XXX
 SG_ EngWaitToStartLamp : 24|2@1+ (1,0) [0|3] "" Vector__XXX
 SG_ RefrigerantHighPressSwitch : 20|2@1+ (1,0) [0|3] "" Vector__XXX
 SG_ RefrigerantLowPressSwitch : 18|2@1+ (1,0) [0|3] "" Vector__XXX
 SG_ A_CHighPressFanSwitch : 16|2@1+ (1,0) [0|3] "" Vector__XXX
 SG_ EngIdleShutdownTimerFunction : 14|2@1+ (1,0) [0|3] "" Vector__XXX
 SG_ EngIdleShutdownTimerState : 6|2@1+ (1,0) [0|3] "" Vector__XXX
 SG_ EngIdleShutdownTimerOverride : 4|2@1+ (1,0) [0|3] "" Vector__XXX
 SG_ EngIdleShutdownDriverAlertMode : 2|2@1+ (1,0) [0|3] "" Vector__XXX
 SG_ EngIdleShutdownHasShutdownEng : 0|2@1+ (1,0) [0|3] "" Vector__XXX

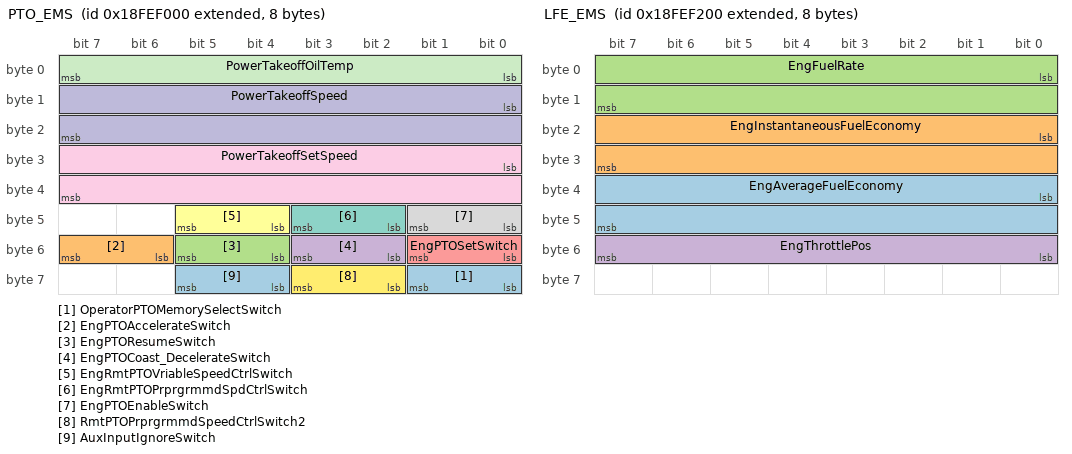
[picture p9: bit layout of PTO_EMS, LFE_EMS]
BO_ 2566844416 PTO_EMS: 8 EMS
 SG_ OperatorPTOMemorySelectSwitch : 56|2@1+ (1,0) [0|3] "" Vector__XXX
 SG_ EngPTOAccelerateSwitch : 54|2@1+ (1,0) [0|3] "" Vector__XXX
 SG_ EngPTOResumeSwitch : 52|2@1+ (1,0) [0|3] "" Vector__XXX
 SG_ EngPTOCoast_DecelerateSwitch : 50|2@1+ (1,0) [0|3] "" Vector__XXX
 SG_ EngPTOSetSwitch : 48|2@1+ (1,0) [0|3] "" Vector__XXX
 SG_ EngRmtPTOVriableSpeedCtrlSwitch : 44|2@1+ (1,0) [0|3] "" Vector__XXX
 SG_ EngRmtPTOPrprgrmmdSpdCtrlSwitch : 42|2@1+ (1,0) [0|3] "" Vector__XXX
 SG_ EngPTOEnableSwitch : 40|2@1+ (1,0) [0|3] "" Vector__XXX
 SG_ PowerTakeoffSetSpeed : 24|16@1+ (0.125,0) [0|8031.875] "RPM" Vector__XXX
 SG_ PowerTakeoffSpeed : 8|16@1+ (0.125,0) [0|8031.875] "RPM" Vector__XXX
 SG_ PowerTakeoffOilTemp : 0|8@1+ (1,-40) [-40|210] "°C" Vector__XXX
 SG_ RmtPTOPrprgrmmdSpeedCtrlSwitch2 : 58|2@1+ (1,0) [0|3] "" Vector__XXX
 SG_ AuxInputIgnoreSwitch : 60|2@1+ (1,0) [0|3] "" Vector__XXX

BO_ 2566844928 LFE_EMS: 8 EMS
 SG_ EngAverageFuelEconomy : 32|16@1+ (0.001953125,0) [0|125.5] "km/L" Vector__XXX
 SG_ EngInstantaneousFuelEconomy : 16|16@1+ (0.001953125,0) [0|125.5] "km/L" Vector__XXX
 SG_ EngFuelRate : 0|16@1+ (0.05,0) [0|3212.75] "L/hr" Vector__XXX
 SG_ EngThrottlePos : 48|8@1+ (0.4,0) [0|100] "%" Vector__XXX

BO_ 2566842624 LFC_EMS: 8 EMS
 SG_ EngTotalFuelUsed : 32|32@1+ (0.5,0) [0|2105540607.5] "L" Vector__XXX
 SG_ EngTripFuel : 0|32@1+ (0.5,0) [0|2105540607.5] "L" Vector__XXX

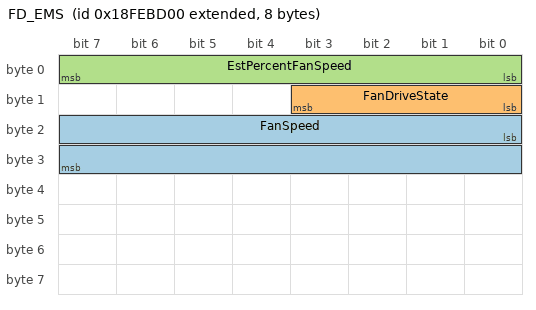
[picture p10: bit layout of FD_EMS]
BO_ 2566831360 FD_EMS: 8 EMS
 SG_ FanSpeed : 16|16@1+ (0.125,0) [0|8031.875] "RPM" Vector__XXX
 SG_ FanDriveState : 8|4@1+ (1,0) [0|15] "" Vector__XXX
 SG_ EstPercentFanSpeed : 0|8@1+ (0.4,0) [0|100] "%" Vector__XXX

CM_ BU_ EMS "Engine Management System";
CM_ BO_ 3221225472 "This is a message for not used signals, created by Vector CANdb++ DBC OLE DB Provider.";
CM_ SG_ 3221225472 SPN5 "SPN #5 (Conversion Version 4)SPN #5 (Conversion Version 4)SPN #5 (Conversion Version 4)SPN #5 (Conversion Version 4)";
CM_ SG_ 3221225472 SPN4 "SPN #4 (Conversion Version 4)SPN #4 (Conversion Version 4)SPN #4 (Conversion Version 4)SPN #4 (Conversion Version 4)";
CM_ SG_ 3221225472 SPN3 "SPN #3 (Conversion Version 4)SPN #3 (Conversion Version 4)SPN #3 (Conversion Version 4)SPN #3 (Conversion Version 4)";
CM_ SG_ 3221225472 SPN2 "SPN #2 (Conversion Version 4)SPN #2 (Conversion Version 4)SPN #2 (Conversion Version 4)SPN #2 (Conversion Version 4)";
CM_ SG_ 3221225472 FailureModeIdentifier5 "The FMI defines the type of failure detected in the subsystem identified by an SPN.The FMI defines the type of failure detected in the subsystem identified by an SPN.The FMI defines the type of failure detected in the subsystem identified by an SPN.The FMI defines the type of failure detected in the subsystem identified by an SPN.";
CM_ SG_ 3221225472 FailureModeIdentifier4 "The FMI defines the type of failure detected in the subsystem identified by an SPN.The FMI defines the type of failure detected in the subsystem identified by an SPN.The FMI defines the type of failure detected in the subsystem identified by an SPN.The FMI defines the type of failure detected in the subsystem identified by an SPN.";
CM_ SG_ 3221225472 FlashRedStopLamp "This parameter provides the capability to flash the RSL (SPN 3039).This parameter provides the capability to flash the RSL (SPN 3039).This parameter provides the capability to flash the RSL (SPN 3039).";
CM_ SG_ 3221225472 FlashProtectLamp "This parameter provides the capability to flash the engine protect lamp (SPN 3041).This parameter provides the capability to flash the engine protect lamp (SPN 3041).This parameter provides the capability to flash the engine protect lamp (SPN 3041).";
CM_ SG_ 3221225472 FlashMalfuncIndicatorLamp "This parameter provides the capability to flash the MIL (SPN 3038).This parameter provides the capability to flash the MIL (SPN 3038).This parameter provides the capability to flash the MIL (SPN 3038).";
CM_ SG_ 3221225472 FlashAmberWarningLamp "This parameter provides the capability to flash the AWL (SPN 3040). This parameter provides the capability to flash the AWL (SPN 3040). This parameter provides the capability to flash the AWL (SPN 3040). ";
CM_ SG_ 3221225472 FailureModeIdentifier3 "The FMI defines the type of failure detected in the subsystem identified by an SPN.The FMI defines the type of failure detected in the subsystem identified by an SPN.The FMI defines the type of failure detected in the subsystem identified by an SPN.The FMI defines the type of failure detected in the subsystem identified by an SPN.";
CM_ SG_ 3221225472 FailureModeIdentifier2 "The FMI defines the type of failure detected in the subsystem identified by an SPN.The FMI defines the type of failure detected in the subsystem identified by an SPN.The FMI defines the type of failure detected in the subsystem identified by an SPN.The FMI defines the type of failure detected in the subsystem identified by an SPN.";
CM_ SG_ 3221225472 OccurenceCount5 "The 7 bit occurence count field contains the number of times a fault has gone from active to previously active.The 7 bit occurence count field contains the number of times a fault has gone from active to previously active.The 7 bit occurence count field contains the number of times a fault has gone from active to previously active.The 7 bit occurence count field contains the number of times a fault has gone from active to previously active.";
CM_ SG_ 3221225472 OccurenceCount4 "The 7 bit occurence count field contains the number of times a fault has gone from active to previously active.The 7 bit occurence count field contains the number of times a fault has gone from active to previously active.The 7 bit occurence count field contains the number of times a fault has gone from active to previously active.The 7 bit occurence count field contains the number of times a fault has gone from active to previously active.";
CM_ SG_ 3221225472 OccurenceCount3 "The 7 bit occurence count field contains the number of times a fault has gone from active to previously active.The 7 bit occurence count field contains the number of times a fault has gone from active to previously active.The 7 bit occurence count field contains the number of times a fault has gone from active to previously active.The 7 bit occurence count field contains the number of times a fault has gone from active to previously active.";
CM_ SG_ 3221225472 OccurenceCount2 "The 7 bit occurence count field contains the number of times a fault has gone from active to previously active.The 7 bit occurence count field contains the number of times a fault has gone from active to previously active.The 7 bit occurence count field contains the number of times a fault has gone from active to previously active.The 7 bit occurence count field contains the number of times a fault has gone from active to previously active.";
CM_ SG_ 3221225472 OccurenceCount1 "The 7 bit occurence count field contains the number of times a fault has gone from active to previously active.The 7 bit occurence count field contains the number of times a fault has gone from active to previously active.The 7 bit occurence count field contains the number of times a fault has gone from active to previously active.The 7 bit occurence count field contains the number of times a fault has gone from active to previously active.The 7 bit occurence count field contains the number of times a faul";
CM_ SG_ 3221225472 FailureModeIdentifier1 "The FMI defines the type of failure detected in the subsystem identified by an SPN.The FMI defines the type of failure detected in the subsystem identified by an SPN.The FMI defines the type of failure detected in the subsystem identified by an SPN.The FMI defines the type of failure detected in the subsystem identified by an SPN.The FMI defines the type of failure detected in the subsystem identified by an SPN.The FMI defines the type of failure detected in the subsystem identified by an SPN.";
CM_ SG_ 3221225472 SPN1 "SPN #1 (Conversion Version 4)SPN #1 (Conversion Version 4)SPN #1 (Conversion Version 4)SPN #1 (Conversion Version 4)SPN #1 (Conversion Version 4)SPN #1 (Conversion Version 4)";
CM_ SG_ 3221225472 MalfunctionIndicatorLampStatus "A lamp used to relay only emissions-related trouble code information.A lamp used to relay only emissions-related trouble code information.A lamp used to relay only emissions-related trouble code information.";
CM_ SG_ 3221225472 RedStopLampState "This lamp is uesed to relay trouble code information that is of a severe enought condition that it warrants stopping the vehicle.This lamp is uesed to relay trouble code information that is of a severe enought condition that it warrants stopping the vehicle.This lamp is uesed to relay trouble code information that is of a severe enought condition that it warrants stopping the vehicle.";
CM_ SG_ 3221225472 AmberWarningLampStatus "This lamp is used to relay trouble code information that is reporting a problem with the vehicle system but the vehicle need
not be immediately stopped.This lamp is used to relay trouble code information that is reporting a problem with the vehicle system but the vehicle need
not be immediately stopped.This lamp is used to relay trouble code information that is reporting a problem with the vehicle system but the vehicle need
not be immediately stopped.";
CM_ SG_ 3221225472 ProtectLampStatus "This lamp is used to relay trouble code informatio that is reporting a problem with a vehicle system that is most
probably not electronic subsystem related.This lamp is used to relay trouble code informatio that is reporting a problem with a vehicle system that is most
probably not electronic subsystem related.This lamp is used to relay trouble code informatio that is reporting a problem with a vehicle system that is most
probably not electronic subsystem related.";
CM_ SG_ 3221225472 SPN5High "SPN #5 (Conversion Version 4)SPN #5 (Conversion Version 4)SPN #5 (Conversion Version 4)SPN #5 (Conversion Version 4)";
CM_ SG_ 3221225472 SPN4High "SPN #4 (Conversion Version 4)SPN #4 (Conversion Version 4)SPN #4 (Conversion Version 4)SPN #4 (Conversion Version 4)";
CM_ SG_ 3221225472 SPN3High "SPN #3 (Conversion Version 4)SPN #3 (Conversion Version 4)SPN #3 (Conversion Version 4)SPN #3 (Conversion Version 4)";
CM_ SG_ 3221225472 SPN2High "SPN #2 (Conversion Version 4)SPN #2 (Conversion Version 4)SPN #2 (Conversion Version 4)SPN #2 (Conversion Version 4)";
CM_ SG_ 3221225472 SPN1High "SPN #1 (Conversion Version 4)SPN #1 (Conversion Version 4)SPN #1 (Conversion Version 4)SPN #1 (Conversion Version 4)SPN #1 (Conversion Version 4)SPN #1 (Conversion Version 4)";
CM_ BO_ 2566843646 "Vehicle Identification";
CM_ BO_ 2566832638 "High Resolution Vehicle Distance";
CM_ SG_ 2566832638 HighResolutionTripDistance "Distance traveled during all or part of a journey.";
CM_ SG_ 2566832638 HghRslutionTotalVehicleDistance "Accumulated distance traveled by the vehicle during its operation.";
CM_ BO_ 2566840574 "Vehicle Distance";
CM_ SG_ 2566840574 TotalVehicleDistance "Accumulated distance traveled by vehicle during its operation.";
CM_ SG_ 2566840574 TripDistance "Distance traveled during all or part of a journey.";
CM_ BO_ 2566839806 "Turbocharger";
CM_ SG_ 2566839806 EngTurbo1Speed "Rotational velocity of rotor in the turbocharger.";
CM_ SG_ 2566839806 EngTurboLubeOilPress1 "Gage pressure of oil in turbocharger lubrication system.";
CM_ BO_ 2566841598 "Shutdown";
CM_ SG_ 2566841598 EngOverspeedTest "The engine overspeed test signal as measured by the reporting ECM.";
CM_ SG_ 2566841598 EngAirShutoffCmdStatus "State signal which indicates when the Air Shutoff driver output is being driven.";
CM_ SG_ 2566841598 EngAlarmOutputCmdStatus "State signal which indicates when the Alarm driver output is being driven.";
CM_ SG_ 2566841598 EngAlarmAcknowledge "The Engine Alarm Acknowledge Input signal as measured by the reporting ECM.";
CM_ SG_ 2566841598 EngProtectionSystemConfig "Parameter which indicates the configuration of the engine shutdown system.";
CM_ SG_ 2566841598 EngProtectionSystemTimerState "Status signal which indicates the current mode of the engine protection system timer system.";
CM_ SG_ 2566841598 EngPrtectionSystemTimerOverride "Status signal which indicates the status of the override feature of the engine protection system timer.";
CM_ SG_ 2566841598 EngPrtctnSystmApprchingShutdown "Status signal which indicates that engine shutdown is imminent.";
CM_ SG_ 2566841598 EngPrtctionSystemHasShutdownEng "Status signal which indicates whether or not the engine protection system has shutdown the engine.";
CM_ SG_ 2566841598 RefrigerantHighPressSwitch "Switch signal which indicates the position of the high pressure switch in the coolant circuit of an air conditioning system.";
CM_ SG_ 2566841598 RefrigerantLowPressSwitch "Switch signal which indicates the position of the low pressure switch in the coolant circuit of an air conditioning system.";
CM_ SG_ 2566841598 EngIdleShutdownTimerFunction "Parameter which indicates the configuration of the idle shutdown timer system.";
CM_ SG_ 2566841598 EngIdleShutdownTimerState "Status signal which indicates the current mode of operation of the idle shutdown timer system.";
CM_ SG_ 2566841598 EngIdleShutdownTimerOverride "Status signal which indicates the status of the override feature of the idle shutdown timer system.";
CM_ SG_ 2566841598 EngIdleShutdownDriverAlertMode "Status signal which indicates the status of the driver alert mode of the idle shutdown timer system.";
CM_ SG_ 2566841598 EngIdleShutdownHasShutdownEng "Status signal which identifies whether or not the engine has been shutdown by the idle shutdown timer system.";
CM_ BO_ 2566844670 "Power Takeoff Information";
CM_ SG_ 2566844670 OperatorPTOMemorySelectSwitch "Measured state of the operator PTO memory select switch.";
CM_ SG_ 2566844670 EngPTOAccelerateSwitch "Switch signal of the PTO control activator which indicates that the activator is in the position accelerate.";
CM_ SG_ 2566844670 EngPTOResumeSwitch "Switch signal of the PTO control activator which indicates that the activator is in the position \"resume\".";
CM_ SG_ 2566844670 EngPTOCoast_DecelerateSwitch "Switch signal of the PTO control activator which indicates that the activator is in the position coast/decelerate.";
CM_ SG_ 2566844670 EngPTOSetSwitch "Switch signal of the PTO control activator which indicates that the activator is in the position set.";
CM_ SG_ 2566844670 EngRmtPTOVriableSpeedCtrlSwitch "Switch signal which indicates that the remote PTO toggle switch is in the enabled (ON) position.";
CM_ SG_ 2566844670 EngRmtPTOPrprgrmmdSpdCtrlSwitch "Switch signal which indicates that the remote PTO toggle switch is in the enabled (ON) position.";
CM_ SG_ 2566844670 EngPTOEnableSwitch "Switch signal which indicates that the PTO governor toggle switch is in the enabled position.";
CM_ SG_ 2566844670 PowerTakeoffSetSpeed "Rotational velocity selected by operator for device used to transmit engine power to auxiliary equipment.";
CM_ SG_ 2566844670 PowerTakeoffSpeed "Rotational velocity of device used to transmit engine power to auxiliary equipment.";
CM_ SG_ 2566844670 PowerTakeoffOilTemp "Temperature of lubricant in device used to transmit engine power to auxiliary equipment.";
CM_ SG_ 2566844670 RmtPTOPrprgrmmdSpeedCtrlSwitch2 "Switch signal which indicates that the remote PTO toggle switch #2 is in the enabled (ON) position.";
CM_ SG_ 2566844670 AuxInputIgnoreSwitch "Switch signal which overrides other switch input's ability to kick out of an engine's operating condition.";
CM_ BO_ 2566845182 "Fuel Economy (Liquid)";
CM_ SG_ 2566845182 EngAverageFuelEconomy "Average of instantaneous fuel economy for that segment of vehicle operation of interest.";
CM_ SG_ 2566845182 EngInstantaneousFuelEconomy "Current fuel economy at current vehicle velocity.";
CM_ SG_ 2566845182 EngFuelRate "Amount of fuel consumed by engine per unit of time.";
CM_ SG_ 2566845182 EngThrottlePos "The position of the valve used to regulate the supply of a fluid, usually air or fuel/air mixture, to an engine.";
CM_ BO_ 2566842878 "Fuel Consumption (Liquid)";
CM_ SG_ 2566842878 EngTotalFuelUsed "Accumulated amount of fuel used during vehicle operation.";
CM_ SG_ 2566842878 EngTripFuel "Fuel consumed during all or part of a journey.";
CM_ BO_ 2566846206 "Inlet/Exhaust Conditions 1";
CM_ SG_ 2566846206 EngExhaustGasTemp "Temperature of combustion byproducts leaving the engine.";
CM_ SG_ 2566846206 EngAirInletPress "Absolute air pressure at inlet to intake manifold or air box.";
CM_ SG_ 2566846206 EngIntakeManifold1Temp "Temperature of pre-combustion air found in intake manifold of engine air supply system.";
CM_ SG_ 2566846206 EngTurboBoostPress "Gage pressure of air measured downstream on the compressor discharge side of the turbocharger.";
CM_ SG_ 2566846206 EngParticulateTrapInletPress "Exhaust back pressure as a result of particle accumulation on filter media placed in the exhaust stream.";
CM_ BO_ 2566841854 "Engine Hours, Revolutions";
CM_ SG_ 2566841854 EngTotalRevolutions "Accumulated number of revolutions of engine crankshaft during its operation.";
CM_ SG_ 2566841854 EngTotalHoursOfOperation "Accumulated time of operation of engine.";
CM_ BO_ 2566831614 "Fan Drive";
CM_ SG_ 2566831614 FanSpeed "The speed of the fan associated with engine coolant system.";
CM_ SG_ 2566831614 FanDriveState "This parameter is used to indicate the current state or mode of operation by the fan drive.";
CM_ SG_ 2566831614 EstPercentFanSpeed "Estimated fan speed as a ratio of the fan drive (current speed) to the fully engaged fan drive (maximum fan speed).";
CM_ BO_ 2566825214 "Engine Temperature 2";
CM_ SG_ 2566825214 EngECUTemp "Temperature of the engine electronic control unit.";
CM_ SG_ 2566825214 EngOilTemp2 "Temperature of the engine lubricant.";
CM_ BO_ 2566844158 "Engine Temperature 1";
CM_ SG_ 2566844158 EngIntercoolerThermostatOpening "The current position of the thermostat used to regulate the temperature of the engine intercooler.";
CM_ SG_ 2566844158 EngIntercoolerTemp "Temperature of liquid found in the intercooler located after the turbocharger.";
CM_ SG_ 2566844158 EngTurboOilTemp "Temperature of the turbocharger lubricant.";
CM_ SG_ 2566844158 EngOilTemp1 "Temperature of the engine lubricant.";
CM_ SG_ 2566844158 EngFuelTemp "Temperature of fuel entering injectors.";
CM_ SG_ 2566844158 EngCoolantTemp "Temperature of liquid found in engine cooling system.";
CM_ BO_ 2633935358 "Exhaust Oxygen 1";
CM_ SG_ 2633935358 EngExhstGsOxygnSnsrClsdLpOprton "Indicates whether the engine is using the Exhaust Gas Oxygen sensor to control the air/fuel ratio.";
CM_ BO_ 2566844160 "Engine Fluid Level/Pressure 1";
CM_ SG_ 2566844160 EngCoolantLevel "Ratio of volume of liquid found in engine cooling system to total cooling system volume.";
CM_ SG_ 2566844160 EngCoolantPress "Gage pressure of liquid found in engine cooling system.";
CM_ SG_ 2566844160 EngCrankcasePress "Gage pressure inside engine crankcase.";
CM_ SG_ 2566844160 EngOilPress "Gage pressure of oil in engine lubrication system as provided by oil pump.";
CM_ SG_ 2566844160 EngOilLevel "Ratio of current volume of engine sump oil to maximum required volume.";
CM_ SG_ 2566844160 EngExCrankcaseBlowbyPress "Differential crankcase blow-by pressure as measured through a tube with a venturi.";
CM_ SG_ 2566844160 EngFuelDeliveryPress "Gage pressure of fuel in system as delivered from supply pump to the injection pump.";
CM_ BO_ 2566840318 "Electronic Engine Controller 3";
CM_ SG_ 2566840318 ExhaustGasMass "Measured/calculated exhaust gas mass upstream of the after-treatment system.";
CM_ SG_ 2566840318 EngsDesiredOperatingSpeed "An indication by the engine of the optimal operating speed of the engine for the current existing conditions.";
CM_ BO_ 2364539902 "Electronic Engine Controller 2";
CM_ SG_ 2364539902 ActMaxAvailEngPercentTorque "This is the maximum amount of torque that the engine can immediately deliver as a percentage of the reference engine torque.";
CM_ SG_ 2364539902 VhclAccelerationRateLimitStatus "Status (active or not active) of the system used to limit maximum forward vehicle acceleration.";
CM_ SG_ 2364539902 AccelPedal2LowIdleSwitch "Switch signal which indicates the state of the accelerator pedal 2 low idle switch.";
CM_ SG_ 2364539902 RoadSpeedLimitStatus "Status (active or not active) of the system used to limit maximum vehicle velocity.";
CM_ SG_ 2364539902 AccelPedalKickdownSwitch "Switch signal which indicates whether the accelerator pedal kickdown switch is opened or closed.";
CM_ SG_ 2364539902 AccelPedal1LowIdleSwitch "Switch signal which indicates the state of the accelerator pedal 1 low idle switch.";
CM_ BO_ 2364540158 "Electronic Engine Controller 1";
CM_ SG_ 2364540158 EngStarterMode "There are several phases in a starting action and different reasons why a start cannot take place.";
CM_ SG_ 2364540158 SrcAddrssOfCtrllngDvcForEngCtrl "The source address of the SAE J1939 device currently controlling the engine.";
CM_ SG_ 2364540158 EngSpeed "Actual engine speed which is calculated over a minimum crankshaft angle of 720 degrees divided by the number of cylinders.";
CM_ SG_ 2364540158 ActualEngPercentTorque "The calculated output torque of the engine.";
CM_ SG_ 2364540158 DriversDemandEngPercentTorque "The requested torque output of the engine by the driver.";
CM_ SG_ 2364540158 EngTorqueMode "State signal which indicates which engine torque mode is currently generating, limiting, or controlling the torque.";
CM_ BO_ 2566841342 "Engine Configuration";
CM_ SG_ 2566841342 SupportTSC1CtrlPurposeGroup4Of4 "This parameter indicates which TSC1 control purposes are supported in group 4 of 4.";
CM_ SG_ 2566841342 SupportTSC1CtrlPurposeGroup3Of4 "This parameter indicates which TSC1 control purposes are supported in group 3 of 4.";
CM_ SG_ 2566841342 SupportTSC1CtrlPurposeGroup2Of4 "This parameter indicates which TSC1 control purposes are supported in group 2 of 4.";
CM_ SG_ 2566841342 SupportTSC1CtrlPurposeGroup1Of4 "This parameter indicates which TSC1 control purposes are supported in group 1 of 4.";
CM_ SG_ 2566841342 EngDefaultTorqueLimit "Companion parameter to Transmission Torque Limit (SPN 1845).";
CM_ SG_ 2566841342 EngMomentOfInertia "Moment of inertia for the engine, including items driven full-time by the engine such as fuel, oil and cooling pumps.";
CM_ SG_ 2566841342 EngRqdTorqueCtrlRangeUpperLimit "The maximum engine torque that the engine will allow when operating in a torque control/limit mode.";
CM_ SG_ 2566841342 EngRqdTorqueCtrlRangeLowerLimit "The minimum engine torque that the engine will allow when operating in a torque control/limit mode.";
CM_ SG_ 2566841342 EngRqedSpeedCtrlRangeLowerLimit "The minimum engine speed that the engine will allow when operating in a speed control/limit mode.";
CM_ SG_ 2566841342 EngMxMomentaryOverrideTimeLimit "The maximum time limit allowed to override the engine's high idle speed.";
CM_ SG_ 2566841342 EngMxMmntaryOverrideSpeedPoint7 "The maximum engine speed above high idle allowed by the engine control during a momentary high idle override.";
CM_ SG_ 2566841342 EngReferenceTorque "This parameter is the 100% reference value for all defined indicated engine torque parameters.";
CM_ SG_ 2566841342 EngSpeedAtHighIdlePoint6 "Engine speed of high idle (point 6) of the engine torque map (see PGN 65251 and supporting document).";
CM_ SG_ 2566841342 EngSpeedAtPoint5 "Engine speed of point 3, 4, and 5 of the engine torque map (see PGN 65251 and supporting document).";
CM_ SG_ 2566841342 EngSpeedAtPoint4 "Engine speed of point 3, 4, and 5 of the engine torque map (see PGN 65251 and supporting document).";
CM_ SG_ 2566841342 EngSpeedAtPoint3 "Engine speed of point 3, 4, and 5 of the engine torque map (see PGN 65251 and supporting document).";
CM_ SG_ 2566841342 EngSpeedAtPoint2 "Engine speed of point 2 of the engine torque map (see PGN 65251 and supporting document).";
CM_ SG_ 2566841342 EngPercentTorqueAtIdlePoint1 "The torque limit that indicates the available engine torque which can be provided by the engine at idle speed.";
CM_ BO_ 2566844926 "Cruise Control/Vehicle Speed";
CM_ SG_ 2566844926 EngShutdownOverrideSwitch "Switch signal which indicates the position of the engine shutdown override switch.";
CM_ SG_ 2566844926 EngTestModeSwitch "Switch signal which indicates the position of the engine test mode switch.";
CM_ SG_ 2566844926 EngIdleDecrementSwitch "Switch signal which indicates the position of the idle decrement switch.";
CM_ SG_ 2566844926 EngIdleIncrementSwitch "Switch signal which indicates the position of the idle increment switch.";
CM_ SG_ 2566844926 CruiseCtrlStates "This parameter is used to indicate the current state, or mode, of operation by the cruise control device.";
CM_ SG_ 2566844926 PTOState "This parameter is used to indicate the current state or mode of operation by the power takeoff (PTO) device.";
CM_ SG_ 2566844926 CruiseCtrlSetSpeed "Value of set (chosen) velocity of velocity control system.";
CM_ SG_ 2566844926 CruiseCtrlAccelerateSwitch "Switch signal of the cruise control activator which indicates that the activator is in the position “accelerate.";
CM_ SG_ 2566844926 CruiseCtrlResumeSwitch "Switch signal of the cruise control activator which indicates that the activator is in the position “resume.";
CM_ SG_ 2566844926 CruiseCtrlCoastSwitch "Switch signal of the cruise control activator which indicates that the activator is in the position “coast (decelerate).";
CM_ SG_ 2566844926 CruiseCtrlSetSwitch "Switch signal of the cruise control activator which indicates that the activator is in the position “set.";
CM_ SG_ 2566844926 ClutchSwitch "Switch signal which indicates that the clutch pedal is being pressed.";
CM_ SG_ 2566844926 BrakeSwitch "Switch signal which indicates that the driver operated brake foot pedal is being pressed.";
CM_ SG_ 2566844926 CruiseCtrlEnableSwitch "Switch signal which indicates that it is possible to manage the cruise control function.";
CM_ SG_ 2566844926 CruiseCtrlActive "Cruise control is switched on.";
CM_ SG_ 2566844926 WheelBasedVehicleSpeed "Speed of the vehicle as calculated from wheel or tailshaft speed.";
CM_ SG_ 2566844926 CruiseCtrlPauseSwitch "Switch signal which indicates the position of the Cruise Control Pause Switch used on Remote Cruise Control applications.";
CM_ SG_ 2566844926 ParkingBrakeSwitch "Switch signal which indicates when the parking brake is set.";
CM_ SG_ 2566844926 TwoSpeedAxleSwitch "Switch signal which indicates the current axle range.";
CM_ BO_ 2566845950 "Ambient Conditions";
CM_ SG_ 2566845950 RoadSurfaceTemp "Indicated temperature of road surface over which vehicle is operating.";
CM_ SG_ 2566845950 EngAirInletTemp "Temperature of air entering vehicle air induction system.";
CM_ SG_ 2566845950 AmbientAirTemp "Temperature of air surrounding vehicle.";
CM_ SG_ 2566845950 CabInteriorTemp "Temperature of air inside the part of the vehicle that encloses the driver and vehicle operating controls.";
CM_ SG_ 2566845950 BarometricPress "Absolute air pressure of the atmosphere.";
CM_ BO_ 2562981630 "Individual Clear/Reset of active and previously active DTC.";
CM_ SG_ 2562981630 SPN1 "SPN #1 (Conversion Version 4)";
CM_ SG_ 2562981630 SPN1High "SPN #1 (Conversion Version 4)";
CM_ SG_ 2562981630 FailureModeIdentifier1 "The FMI defines the type of failure detected in the subsystem identified by an SPN.";
CM_ BO_ 2348875518 "Torque/Speed Control 1";
CM_ SG_ 2348875518 EngineRequestedTorqueHiRes "This parameter displays an additional torque in percent of the reference engine torque.";
CM_ SG_ 2348875518 ControlPurpose "State signal which indicates which control mode the sending device is using to generate the TSC1 command.";
CM_ SG_ 2348875518 TransmissionRate "This parameter indicates the transmission rate at which the sending device will transmit the TSC1 message.";
CM_ SG_ 2348875518 EngRqedTorque_TorqueLimit "Parameter provided to the engine or retarder in the torque/speed control message for controlling or limiting the output torque.";
CM_ SG_ 2348875518 EngRqedSpeed_SpeedLimit "Parameter provided to the engine from external sources in the torque/speed control message.";
CM_ SG_ 2348875518 EngRqedSpeedCtrlConditions "This mode tells the engine control system the governor characteristics that are desired during speed control.";
CM_ BO_ 2566837246 "Diagnostic data clear/Reset for active DTCs";
CM_ BO_ 2566845952 "Inlet/Exhaust Conditions 1";
CM_ SG_ 2566845952 EngExhaustGasTemp "Temperature of combustion byproducts leaving the engine.";
CM_ SG_ 2566845952 EngAirInletPress "Absolute air pressure at inlet to intake manifold or air box.";
CM_ SG_ 2566845952 EngIntakeManifold1Temp "Temperature of pre-combustion air found in intake manifold of engine air supply system.";
CM_ SG_ 2566845952 EngTurboBoostPress "Gage pressure of air measured downstream on the compressor discharge side of the turbocharger.";
CM_ SG_ 2566845952 EngParticulateTrapInletPress "Exhaust back pressure as a result of particle accumulation on filter media placed in the exhaust stream.";
CM_ BO_ 2566841600 "Engine Hours, Revolutions";
CM_ SG_ 2566841600 EngTotalRevolutions "Accumulated number of revolutions of engine crankshaft during its operation.";
CM_ SG_ 2566841600 EngTotalHoursOfOperation "Accumulated time of operation of engine.";
CM_ BO_ 2566843392 "Vehicle Identification";
CM_ BO_ 2566832384 "High Resolution Vehicle Distance";
CM_ SG_ 2566832384 HighResolutionTripDistance "Distance traveled during all or part of a journey.";
CM_ SG_ 2566832384 HghRslutionTotalVehicleDistance "Accumulated distance traveled by the vehicle during its operation.";
CM_ BO_ 2566840320 "Vehicle Distance";
CM_ SG_ 2566840320 TotalVehicleDistance "Accumulated distance traveled by vehicle during its operation.";
CM_ SG_ 2566840320 TripDistance "Distance traveled during all or part of a journey.";
CM_ BO_ 2566839552 "Turbocharger";
CM_ SG_ 2566839552 EngTurbo1Speed "Rotational velocity of rotor in the turbocharger.";
CM_ SG_ 2566839552 EngTurboLubeOilPress1 "Gage pressure of oil in turbocharger lubrication system.";
CM_ BO_ 2566839038 "Software Identification";
CM_ SG_ 2566839038 SoftwareID3 "Software ID";
CM_ SG_ 2566839038 SoftwareID2 "Software ID";
CM_ SG_ 2566839038 SoftwareID1 "Software ID";
CM_ SG_ 2566839038 NmbrOfSftwrIdentificationFields "Number of software identification designators represented in the software identification parameter group.";
CM_ BO_ 2566841344 "Shutdown";
CM_ SG_ 2566841344 EngOverspeedTest "The engine overspeed test signal as measured by the reporting ECM.";
CM_ SG_ 2566841344 EngAirShutoffCmdStatus "State signal which indicates when the Air Shutoff driver output is being driven.";
CM_ SG_ 2566841344 EngAlarmOutputCmdStatus "State signal which indicates when the Alarm driver output is being driven.";
CM_ SG_ 2566841344 EngAlarmAcknowledge "The Engine Alarm Acknowledge Input signal as measured by the reporting ECM.";
CM_ SG_ 2566841344 EngProtectionSystemConfig "Parameter which indicates the configuration of the engine shutdown system.";
CM_ SG_ 2566841344 EngProtectionSystemTimerState "Status signal which indicates the current mode of the engine protection system timer system.";
CM_ SG_ 2566841344 EngPrtectionSystemTimerOverride "Status signal which indicates the status of the override feature of the engine protection system timer.";
CM_ SG_ 2566841344 EngPrtctnSystmApprchingShutdown "Status signal which indicates that engine shutdown is imminent.";
CM_ SG_ 2566841344 EngPrtctionSystemHasShutdownEng "Status signal which indicates whether or not the engine protection system has shutdown the engine.";
CM_ SG_ 2566841344 RefrigerantHighPressSwitch "Switch signal which indicates the position of the high pressure switch in the coolant circuit of an air conditioning system.";
CM_ SG_ 2566841344 RefrigerantLowPressSwitch "Switch signal which indicates the position of the low pressure switch in the coolant circuit of an air conditioning system.";
CM_ SG_ 2566841344 EngIdleShutdownTimerFunction "Parameter which indicates the configuration of the idle shutdown timer system.";
CM_ SG_ 2566841344 EngIdleShutdownTimerState "Status signal which indicates the current mode of operation of the idle shutdown timer system.";
CM_ SG_ 2566841344 EngIdleShutdownTimerOverride "Status signal which indicates the status of the override feature of the idle shutdown timer system.";
CM_ SG_ 2566841344 EngIdleShutdownDriverAlertMode "Status signal which indicates the status of the driver alert mode of the idle shutdown timer system.";
CM_ SG_ 2566841344 EngIdleShutdownHasShutdownEng "Status signal which identifies whether or not the engine has been shutdown by the idle shutdown timer system.";
CM_ BO_ 2566844416 "Power Takeoff Information";
CM_ SG_ 2566844416 OperatorPTOMemorySelectSwitch "Measured state of the operator PTO memory select switch.";
CM_ SG_ 2566844416 EngPTOAccelerateSwitch "Switch signal of the PTO control activator which indicates that the activator is in the position accelerate.";
CM_ SG_ 2566844416 EngPTOResumeSwitch "Switch signal of the PTO control activator which indicates that the activator is in the position \"resume\".";
CM_ SG_ 2566844416 EngPTOCoast_DecelerateSwitch "Switch signal of the PTO control activator which indicates that the activator is in the position coast/decelerate.";
CM_ SG_ 2566844416 EngPTOSetSwitch "Switch signal of the PTO control activator which indicates that the activator is in the position set.";
CM_ SG_ 2566844416 EngRmtPTOVriableSpeedCtrlSwitch "Switch signal which indicates that the remote PTO toggle switch is in the enabled (ON) position.";
CM_ SG_ 2566844416 EngRmtPTOPrprgrmmdSpdCtrlSwitch "Switch signal which indicates that the remote PTO toggle switch is in the enabled (ON) position.";
CM_ SG_ 2566844416 EngPTOEnableSwitch "Switch signal which indicates that the PTO governor toggle switch is in the enabled position.";
CM_ SG_ 2566844416 PowerTakeoffSetSpeed "Rotational velocity selected by operator for device used to transmit engine power to auxiliary equipment.";
CM_ SG_ 2566844416 PowerTakeoffSpeed "Rotational velocity of device used to transmit engine power to auxiliary equipment.";
CM_ SG_ 2566844416 PowerTakeoffOilTemp "Temperature of lubricant in device used to transmit engine power to auxiliary equipment.";
CM_ SG_ 2566844416 RmtPTOPrprgrmmdSpeedCtrlSwitch2 "Switch signal which indicates that the remote PTO toggle switch #2 is in the enabled (ON) position.";
CM_ SG_ 2566844416 AuxInputIgnoreSwitch "Switch signal which overrides other switch input's ability to kick out of an engine's operating condition.";
CM_ BO_ 2566844928 "Fuel Economy (Liquid)";
CM_ SG_ 2566844928 EngAverageFuelEconomy "Average of instantaneous fuel economy for that segment of vehicle operation of interest.";
CM_ SG_ 2566844928 EngInstantaneousFuelEconomy "Current fuel economy at current vehicle velocity.";
CM_ SG_ 2566844928 EngFuelRate "Amount of fuel consumed by engine per unit of time.";
CM_ SG_ 2566844928 EngThrottlePos "The position of the valve used to regulate the supply of a fluid, usually air or fuel/air mixture, to an engine.";
CM_ BO_ 2566842624 "Fuel Consumption (Liquid)";
CM_ SG_ 2566842624 EngTotalFuelUsed "Accumulated amount of fuel used during vehicle operation.";
CM_ SG_ 2566842624 EngTripFuel "Fuel consumed during all or part of a journey.";
CM_ BO_ 2566831360 "Fan Drive";
CM_ SG_ 2566831360 FanSpeed "The speed of the fan associated with engine coolant system.";
CM_ SG_ 2566831360 FanDriveState "This parameter is used to indicate the current state or mode of operation by the fan drive.";
CM_ SG_ 2566831360 EstPercentFanSpeed "Estimated fan speed as a ratio of the fan drive (current speed) to the fully engaged fan drive (maximum fan speed).";
BA_DEF_ SG_  "GenSigEVName" STRING ;
BA_DEF_ SG_  "GenSigSendType" ENUM  "Cyclic","OnWrite","reserved","OnChange","reserved","reserved","reserved","NoSigSendType";
BA_DEF_ SG_  "GenSigILSupport" ENUM  "Yes","No";
BA_DEF_ BO_  "GenMsgILSupport" ENUM  "Yes","No";
BA_DEF_ SG_  "SigType" ENUM  "Default","Range","RangeSigned","ASCII","Discrete","Control","ReferencePGN","DTC","StringDelimiter","StringLength","StringLengthControl";
BA_DEF_ SG_  "SPN" INT 0 524287;
BA_DEF_ BO_  "GenMsgRequestable" INT 0 1;
BA_DEF_ BO_  "GenMsgSendType" ENUM  "cyclic","reserved","cyclicIfActive","reserved","reserved","reserved","reserved","reserved","noMsgSendType";
BA_DEF_ BO_  "VFrameFormat" ENUM  "StandardCAN","ExtendedCAN","reserved","J1939PG";
BA_DEF_ BO_  "GenMsgCycleTime" INT 0 3600000;
BA_DEF_ BU_  "NodeLayerModules" STRING ;
BA_DEF_ BU_  "NmStationAddress" INT 0 255;
BA_DEF_ BU_  "NmJ1939AAC" INT 0 1;
BA_DEF_ BU_  "NmJ1939IndustryGroup" INT 0 7;
BA_DEF_ BU_  "NmJ1939System" INT 0 127;
BA_DEF_ BU_  "NmJ1939SystemInstance" INT 0 15;
BA_DEF_ BU_  "NmJ1939Function" INT 0 255;
BA_DEF_ BU_  "NmJ1939FunctionInstance" INT 0 7;
BA_DEF_ BU_  "NmJ1939ECUInstance" INT 0 7;
BA_DEF_ BU_  "NmJ1939ManufacturerCode" INT 0 2047;
BA_DEF_ BU_  "NmJ1939IdentityNumber" INT 0 2097151;
BA_DEF_ BU_  "ECU" STRING ;
BA_DEF_  "DatabaseVersion" STRING ;
BA_DEF_  "BusType" STRING ;
BA_DEF_  "ProtocolType" STRING ;
BA_DEF_  "SAE_J1939_21_SpecVersion" STRING ;
BA_DEF_  "SAE_J1939_73_SpecVersion" STRING ;
BA_DEF_  "SAE_J1939_71_SpecVersion" STRING ;
BA_DEF_DEF_  "GenSigEVName" "Env@Nodename_@Signame";
BA_DEF_DEF_  "GenSigSendType" "NoSigSendType";
BA_DEF_DEF_  "GenSigILSupport" "Yes";
BA_DEF_DEF_  "GenMsgILSupport" "Yes";
BA_DEF_DEF_  "SigType" "Default";
BA_DEF_DEF_  "SPN" 0;
BA_DEF_DEF_  "GenMsgRequestable" 1;
BA_DEF_DEF_  "GenMsgSendType" "noMsgSendType";
BA_DEF_DEF_  "VFrameFormat" "J1939PG";
BA_DEF_DEF_  "GenMsgCycleTime" 0;
BA_DEF_DEF_  "NodeLayerModules" "";
BA_DEF_DEF_  "NmStationAddress" 254;
BA_DEF_DEF_  "NmJ1939AAC" 0;
BA_DEF_DEF_  "NmJ1939IndustryGroup" 0;
BA_DEF_DEF_  "NmJ1939System" 0;
BA_DEF_DEF_  "NmJ1939SystemInstance" 0;
BA_DEF_DEF_  "NmJ1939Function" 0;
BA_DEF_DEF_  "NmJ1939FunctionInstance" 0;
BA_DEF_DEF_  "NmJ1939ECUInstance" 0;
BA_DEF_DEF_  "NmJ1939ManufacturerCode" 0;
BA_DEF_DEF_  "NmJ1939IdentityNumber" 0;
BA_DEF_DEF_  "ECU" "";
BA_DEF_DEF_  "DatabaseVersion" "";
BA_DEF_DEF_  "BusType" "";
BA_DEF_DEF_  "ProtocolType" "";
BA_DEF_DEF_  "SAE_J1939_21_SpecVersion" "";
BA_DEF_DEF_  "SAE_J1939_73_SpecVersion" "";
BA_DEF_DEF_  "SAE_J1939_71_SpecVersion" "";
BA_ "BusType" "CAN";
BA_ "ProtocolType" "J1939";
BA_ "SAE_J1939_21_SpecVersion" "2004-10-21";
BA_ "SAE_J1939_73_SpecVersion" "2004-09-17";
BA_ "SAE_J1939_71_SpecVersion" "2005-06-01";
BA_ "DatabaseVersion" "7.0";
BA_ "ECU" BU_ Tester "Tester";
BA_ "NmJ1939IdentityNumber" BU_ Tester 609181;
BA_ "NmJ1939ManufacturerCode" BU_ Tester 1861;
BA_ "NmJ1939Function" BU_ Tester 128;
BA_ "NmStationAddress" BU_ Tester 252;
BA_ "NodeLayerModules" BU_ EMS "J1939_IL.dll";
BA_ "ECU" BU_ EMS "EMS";
BA_ "NmJ1939IdentityNumber" BU_ EMS 603212;
BA_ "NmJ1939ManufacturerCode" BU_ EMS 1861;
BA_ "NmStationAddress" BU_ EMS 0;
BA_ "GenMsgCycleTime" BO_ 2566832638 1000;
BA_ "GenMsgSendType" BO_ 2566832638 0;
BA_ "GenMsgCycleTime" BO_ 2566840574 100;
BA_ "GenMsgSendType" BO_ 2566840574 0;
BA_ "GenMsgCycleTime" BO_ 2566839806 1000;
BA_ "GenMsgSendType" BO_ 2566839806 0;
BA_ "GenMsgCycleTime" BO_ 2566841598 1000;
BA_ "GenMsgSendType" BO_ 2566841598 0;
BA_ "GenMsgCycleTime" BO_ 2566844670 100;
BA_ "GenMsgSendType" BO_ 2566844670 0;
BA_ "GenMsgCycleTime" BO_ 2566845182 100;
BA_ "GenMsgSendType" BO_ 2566845182 0;
BA_ "GenMsgCycleTime" BO_ 2566846206 500;
BA_ "GenMsgSendType" BO_ 2566846206 0;
BA_ "GenMsgCycleTime" BO_ 2566831614 1000;
BA_ "GenMsgSendType" BO_ 2566831614 0;
BA_ "GenMsgCycleTime" BO_ 2566825214 1000;
BA_ "GenMsgSendType" BO_ 2566825214 0;
BA_ "GenMsgCycleTime" BO_ 2566844158 1000;
BA_ "GenMsgSendType" BO_ 2566844158 0;
BA_ "GenMsgCycleTime" BO_ 2566844160 500;
BA_ "GenMsgSendType" BO_ 2566844160 0;
BA_ "GenMsgCycleTime" BO_ 2566840318 250;
BA_ "GenMsgSendType" BO_ 2566840318 0;
BA_ "GenMsgCycleTime" BO_ 2364539902 50;
BA_ "GenMsgSendType" BO_ 2364539902 0;
BA_ "GenMsgCycleTime" BO_ 2364540158 100;
BA_ "GenMsgSendType" BO_ 2364540158 0;
BA_ "GenMsgSendType" BO_ 2566844926 0;
BA_ "GenMsgCycleTime" BO_ 2566844926 100;
BA_ "GenMsgSendType" BO_ 2566845950 0;
BA_ "GenMsgCycleTime" BO_ 2566845950 1000;
BA_ "GenMsgSendType" BO_ 2566845952 0;
BA_ "GenMsgCycleTime" BO_ 2566845952 500;
BA_ "GenMsgSendType" BO_ 2566832384 0;
BA_ "GenMsgCycleTime" BO_ 2566832384 1000;
BA_ "GenMsgSendType" BO_ 2566840320 0;
BA_ "GenMsgCycleTime" BO_ 2566840320 100;
BA_ "GenMsgSendType" BO_ 2566839552 0;
BA_ "GenMsgCycleTime" BO_ 2566839552 1000;
BA_ "GenMsgSendType" BO_ 2566841344 0;
BA_ "GenMsgCycleTime" BO_ 2566841344 1000;
BA_ "GenMsgSendType" BO_ 2566844416 0;
BA_ "GenMsgCycleTime" BO_ 2566844416 100;
BA_ "GenMsgSendType" BO_ 2566844928 0;
BA_ "GenMsgCycleTime" BO_ 2566844928 100;
BA_ "GenMsgSendType" BO_ 2566831360 0;
BA_ "GenMsgCycleTime" BO_ 2566831360 1000;
BA_ "SPN" SG_ 3221225472 FlashRedStopLamp 3039;
BA_ "SPN" SG_ 3221225472 FlashProtectLamp 3041;
BA_ "SigType" SG_ 3221225472 FlashMalfuncIndicatorLamp 1.7E-308;
BA_ "SPN" SG_ 3221225472 FlashMalfuncIndicatorLamp 3038;
BA_ "SPN" SG_ 3221225472 FlashAmberWarningLamp 3040;
BA_ "SigType" SG_ 3221225472 OccurenceCount5 1.7E-308;
BA_ "SigType" SG_ 3221225472 OccurenceCount4 1.7E-308;
BA_ "SigType" SG_ 3221225472 OccurenceCount3 1.7E-308;
BA_ "SigType" SG_ 3221225472 OccurenceCount2 1.7E-308;
BA_ "SigType" SG_ 3221225472 OccurenceCount1 1.7E-308;
BA_ "SPN" SG_ 3221225472 OccurenceCount1 1216;
BA_ "SPN" SG_ 3221225472 SPNConversionMethod1 1706;
BA_ "SPN" SG_ 3221225472 FailureModeIdentifier1 1215;
BA_ "SPN" SG_ 3221225472 SPN1 1214;
BA_ "SigType" SG_ 3221225472 MalfunctionIndicatorLampStatus 1.7E-308;
BA_ "SPN" SG_ 3221225472 MalfunctionIndicatorLampStatus 1213;
BA_ "SigType" SG_ 3221225472 RedStopLampState 1.7E-308;
BA_ "SPN" SG_ 3221225472 RedStopLampState 623;
BA_ "SigType" SG_ 3221225472 AmberWarningLampStatus 1.7E-308;
BA_ "SPN" SG_ 3221225472 AmberWarningLampStatus 624;
BA_ "SigType" SG_ 3221225472 ProtectLampStatus 1.7E-308;
BA_ "SPN" SG_ 3221225472 ProtectLampStatus 987;
BA_ "SPN" SG_ 3221225472 SPN1High 1214;
BA_ "SigType" SG_ 2566832638 HighResolutionTripDistance 1;
BA_ "SPN" SG_ 2566832638 HighResolutionTripDistance 918;
BA_ "SigType" SG_ 2566832638 HghRslutionTotalVehicleDistance 1;
BA_ "SPN" SG_ 2566832638 HghRslutionTotalVehicleDistance 917;
BA_ "SigType" SG_ 2566840574 TotalVehicleDistance 1;
BA_ "SPN" SG_ 2566840574 TotalVehicleDistance 245;
BA_ "SigType" SG_ 2566840574 TripDistance 1;
BA_ "SPN" SG_ 2566840574 TripDistance 244;
BA_ "SigType" SG_ 2566839806 EngTurboOilLevelSwitch 4;
BA_ "SPN" SG_ 2566839806 EngTurboOilLevelSwitch 1665;
BA_ "SigType" SG_ 2566839806 EngTurbo1Speed 1;
BA_ "SPN" SG_ 2566839806 EngTurbo1Speed 103;
BA_ "SigType" SG_ 2566839806 EngTurboLubeOilPress1 1;
BA_ "SPN" SG_ 2566839806 EngTurboLubeOilPress1 104;
BA_ "SigType" SG_ 2566841598 EngOverspeedTest 4;
BA_ "SPN" SG_ 2566841598 EngOverspeedTest 2812;
BA_ "SigType" SG_ 2566841598 EngAirShutoffCmdStatus 4;
BA_ "SPN" SG_ 2566841598 EngAirShutoffCmdStatus 2813;
BA_ "SigType" SG_ 2566841598 EngAlarmOutputCmdStatus 4;
BA_ "SPN" SG_ 2566841598 EngAlarmOutputCmdStatus 2814;
BA_ "SigType" SG_ 2566841598 EngAlarmAcknowledge 4;
BA_ "SPN" SG_ 2566841598 EngAlarmAcknowledge 2815;
BA_ "SigType" SG_ 2566841598 EngProtectionSystemConfig 4;
BA_ "SPN" SG_ 2566841598 EngProtectionSystemConfig 1111;
BA_ "SigType" SG_ 2566841598 EngProtectionSystemTimerState 4;
BA_ "SPN" SG_ 2566841598 EngProtectionSystemTimerState 1107;
BA_ "SigType" SG_ 2566841598 EngPrtectionSystemTimerOverride 4;
BA_ "SPN" SG_ 2566841598 EngPrtectionSystemTimerOverride 1108;
BA_ "SigType" SG_ 2566841598 EngPrtctnSystmApprchingShutdown 4;
BA_ "SPN" SG_ 2566841598 EngPrtctnSystmApprchingShutdown 1109;
BA_ "SigType" SG_ 2566841598 EngPrtctionSystemHasShutdownEng 4;
BA_ "SPN" SG_ 2566841598 EngPrtctionSystemHasShutdownEng 1110;
BA_ "SigType" SG_ 2566841598 EngWaitToStartLamp 4;
BA_ "SPN" SG_ 2566841598 EngWaitToStartLamp 1081;
BA_ "SigType" SG_ 2566841598 RefrigerantHighPressSwitch 4;
BA_ "SPN" SG_ 2566841598 RefrigerantHighPressSwitch 605;
BA_ "SigType" SG_ 2566841598 RefrigerantLowPressSwitch 4;
BA_ "SPN" SG_ 2566841598 RefrigerantLowPressSwitch 875;
BA_ "SigType" SG_ 2566841598 A_CHighPressFanSwitch 4;
BA_ "SPN" SG_ 2566841598 A_CHighPressFanSwitch 985;
BA_ "SigType" SG_ 2566841598 EngIdleShutdownTimerFunction 4;
BA_ "SPN" SG_ 2566841598 EngIdleShutdownTimerFunction 591;
BA_ "SigType" SG_ 2566841598 EngIdleShutdownTimerState 4;
BA_ "SPN" SG_ 2566841598 EngIdleShutdownTimerState 590;
BA_ "SigType" SG_ 2566841598 EngIdleShutdownTimerOverride 4;
BA_ "SPN" SG_ 2566841598 EngIdleShutdownTimerOverride 592;
BA_ "SigType" SG_ 2566841598 EngIdleShutdownDriverAlertMode 4;
BA_ "SPN" SG_ 2566841598 EngIdleShutdownDriverAlertMode 594;
BA_ "SigType" SG_ 2566841598 EngIdleShutdownHasShutdownEng 4;
BA_ "SPN" SG_ 2566841598 EngIdleShutdownHasShutdownEng 593;
BA_ "SigType" SG_ 2566844670 OperatorPTOMemorySelectSwitch 4;
BA_ "SPN" SG_ 2566844670 OperatorPTOMemorySelectSwitch 2897;
BA_ "SigType" SG_ 2566844670 EngPTOAccelerateSwitch 4;
BA_ "SPN" SG_ 2566844670 EngPTOAccelerateSwitch 981;
BA_ "SigType" SG_ 2566844670 EngPTOResumeSwitch 4;
BA_ "SPN" SG_ 2566844670 EngPTOResumeSwitch 982;
BA_ "SigType" SG_ 2566844670 EngPTOCoast_DecelerateSwitch 4;
BA_ "SPN" SG_ 2566844670 EngPTOCoast_DecelerateSwitch 983;
BA_ "SigType" SG_ 2566844670 EngPTOSetSwitch 4;
BA_ "SPN" SG_ 2566844670 EngPTOSetSwitch 984;
BA_ "SigType" SG_ 2566844670 EngRmtPTOVriableSpeedCtrlSwitch 4;
BA_ "SPN" SG_ 2566844670 EngRmtPTOVriableSpeedCtrlSwitch 978;
BA_ "SigType" SG_ 2566844670 EngRmtPTOPrprgrmmdSpdCtrlSwitch 4;
BA_ "SPN" SG_ 2566844670 EngRmtPTOPrprgrmmdSpdCtrlSwitch 979;
BA_ "SigType" SG_ 2566844670 EngPTOEnableSwitch 4;
BA_ "SPN" SG_ 2566844670 EngPTOEnableSwitch 980;
BA_ "SigType" SG_ 2566844670 PowerTakeoffSetSpeed 1;
BA_ "SPN" SG_ 2566844670 PowerTakeoffSetSpeed 187;
BA_ "SigType" SG_ 2566844670 PowerTakeoffSpeed 1;
BA_ "SPN" SG_ 2566844670 PowerTakeoffSpeed 186;
BA_ "SigType" SG_ 2566844670 PowerTakeoffOilTemp 1;
BA_ "SPN" SG_ 2566844670 PowerTakeoffOilTemp 90;
BA_ "SigType" SG_ 2566844670 RmtPTOPrprgrmmdSpeedCtrlSwitch2 4;
BA_ "SPN" SG_ 2566844670 RmtPTOPrprgrmmdSpeedCtrlSwitch2 3447;
BA_ "SigType" SG_ 2566844670 AuxInputIgnoreSwitch 4;
BA_ "SPN" SG_ 2566844670 AuxInputIgnoreSwitch 3448;
BA_ "SigType" SG_ 2566845182 EngAverageFuelEconomy 1;
BA_ "SPN" SG_ 2566845182 EngAverageFuelEconomy 185;
BA_ "SigType" SG_ 2566845182 EngInstantaneousFuelEconomy 1;
BA_ "SPN" SG_ 2566845182 EngInstantaneousFuelEconomy 184;
BA_ "SigType" SG_ 2566845182 EngFuelRate 1;
BA_ "SPN" SG_ 2566845182 EngFuelRate 183;
BA_ "SigType" SG_ 2566845182 EngThrottlePos 1;
BA_ "SPN" SG_ 2566845182 EngThrottlePos 51;
BA_ "SigType" SG_ 2566842878 EngTotalFuelUsed 1;
BA_ "SPN" SG_ 2566842878 EngTotalFuelUsed 250;
BA_ "SigType" SG_ 2566842878 EngTripFuel 1;
BA_ "SPN" SG_ 2566842878 EngTripFuel 182;
BA_ "SigType" SG_ 2566846206 EngCoolantFilterDiffPress 1;
BA_ "SPN" SG_ 2566846206 EngCoolantFilterDiffPress 112;
BA_ "SigType" SG_ 2566846206 EngExhaustGasTemp 1;
BA_ "SPN" SG_ 2566846206 EngExhaustGasTemp 173;
BA_ "SigType" SG_ 2566846206 EngAirFilter1DiffPress 1;
BA_ "SPN" SG_ 2566846206 EngAirFilter1DiffPress 107;
BA_ "SigType" SG_ 2566846206 EngAirInletPress 1;
BA_ "SPN" SG_ 2566846206 EngAirInletPress 106;
BA_ "SigType" SG_ 2566846206 EngIntakeManifold1Temp 1;
BA_ "SPN" SG_ 2566846206 EngIntakeManifold1Temp 105;
BA_ "SigType" SG_ 2566846206 EngTurboBoostPress 1.7E-308;
BA_ "SPN" SG_ 2566846206 EngTurboBoostPress 102;
BA_ "SigType" SG_ 2566846206 EngParticulateTrapInletPress 1;
BA_ "SPN" SG_ 2566846206 EngParticulateTrapInletPress 81;
BA_ "SigType" SG_ 2566841854 EngTotalRevolutions 1;
BA_ "SPN" SG_ 2566841854 EngTotalRevolutions 249;
BA_ "SigType" SG_ 2566841854 EngTotalHoursOfOperation 1;
BA_ "SPN" SG_ 2566841854 EngTotalHoursOfOperation 247;
BA_ "SigType" SG_ 2566831614 FanSpeed 1;
BA_ "SPN" SG_ 2566831614 FanSpeed 1639;
BA_ "SigType" SG_ 2566831614 FanDriveState 4;
BA_ "SPN" SG_ 2566831614 FanDriveState 977;
BA_ "SigType" SG_ 2566831614 EstPercentFanSpeed 1;
BA_ "SPN" SG_ 2566831614 EstPercentFanSpeed 975;
BA_ "SigType" SG_ 2566825214 EngExhaustGasRecirculationTemp 1;
BA_ "SPN" SG_ 2566825214 EngExhaustGasRecirculationTemp 412;
BA_ "SigType" SG_ 2566825214 EngExhstGsRcirculationDiffPress 1;
BA_ "SPN" SG_ 2566825214 EngExhstGsRcirculationDiffPress 411;
BA_ "SigType" SG_ 2566825214 EngECUTemp 1;
BA_ "SPN" SG_ 2566825214 EngECUTemp 1136;
BA_ "SigType" SG_ 2566825214 EngOilTemp2 1;
BA_ "SPN" SG_ 2566825214 EngOilTemp2 1135;
BA_ "SigType" SG_ 2566844158 EngIntercoolerThermostatOpening 1;
BA_ "SPN" SG_ 2566844158 EngIntercoolerThermostatOpening 1134;
BA_ "SigType" SG_ 2566844158 EngIntercoolerTemp 1;
BA_ "SPN" SG_ 2566844158 EngIntercoolerTemp 52;
BA_ "SigType" SG_ 2566844158 EngTurboOilTemp 1;
BA_ "SPN" SG_ 2566844158 EngTurboOilTemp 176;
BA_ "SigType" SG_ 2566844158 EngOilTemp1 1;
BA_ "SPN" SG_ 2566844158 EngOilTemp1 175;
BA_ "SigType" SG_ 2566844158 EngFuelTemp 1;
BA_ "SPN" SG_ 2566844158 EngFuelTemp 174;
BA_ "SigType" SG_ 2566844158 EngCoolantTemp 1;
BA_ "SPN" SG_ 2566844158 EngCoolantTemp 110;
BA_ "SigType" SG_ 2633935358 EngExhstGsOxygnSnsrClsdLpOprton 4;
BA_ "SPN" SG_ 2633935358 EngExhstGsOxygnSnsrClsdLpOprton 1696;
BA_ "SigType" SG_ 2633935358 EngExhstGsOxygnSnsrFlngCrrction 1;
BA_ "SPN" SG_ 2633935358 EngExhstGsOxygnSnsrFlngCrrction 1695;
BA_ "SigType" SG_ 2633935358 EngActualExhaustOxygen 1;
BA_ "SPN" SG_ 2633935358 EngActualExhaustOxygen 1119;
BA_ "SigType" SG_ 2633935358 EngDesiredExhaustOxygen 1;
BA_ "SPN" SG_ 2633935358 EngDesiredExhaustOxygen 1118;
BA_ "SigType" SG_ 2633935358 EngDesiredRatedExhaustOxygen 1;
BA_ "SPN" SG_ 2633935358 EngDesiredRatedExhaustOxygen 1117;
BA_ "SigType" SG_ 2566844160 EngCoolantLevel 1;
BA_ "SPN" SG_ 2566844160 EngCoolantLevel 111;
BA_ "SigType" SG_ 2566844160 EngCoolantPress 1;
BA_ "SPN" SG_ 2566844160 EngCoolantPress 109;
BA_ "SigType" SG_ 2566844160 EngCrankcasePress 1;
BA_ "SPN" SG_ 2566844160 EngCrankcasePress 101;
BA_ "SigType" SG_ 2566844160 EngOilPress 1;
BA_ "SPN" SG_ 2566844160 EngOilPress 100;
BA_ "SigType" SG_ 2566844160 EngOilLevel 1;
BA_ "SPN" SG_ 2566844160 EngOilLevel 98;
BA_ "SigType" SG_ 2566844160 EngExCrankcaseBlowbyPress 1;
BA_ "SPN" SG_ 2566844160 EngExCrankcaseBlowbyPress 22;
BA_ "SigType" SG_ 2566844160 EngFuelDeliveryPress 1;
BA_ "SPN" SG_ 2566844160 EngFuelDeliveryPress 94;
BA_ "SigType" SG_ 2566840318 ExhaustGasMass 1;
BA_ "SPN" SG_ 2566840318 ExhaustGasMass 3236;
BA_ "SPN" SG_ 2566840318 AftrTrtmntIntakeDewPointMessage 3237;
BA_ "SPN" SG_ 2566840318 AftrTrtmntExhustDewPointMessage 3238;
BA_ "SigType" SG_ 2566840318 EstEngPrsticLossesPercentTorque 1;
BA_ "SPN" SG_ 2566840318 EstEngPrsticLossesPercentTorque 2978;
BA_ "SigType" SG_ 2566840318 EngsDsrdOprtngSpdAsymmtryAdjstmn 1;
BA_ "SPN" SG_ 2566840318 EngsDsrdOprtngSpdAsymmtryAdjstmn 519;
BA_ "SigType" SG_ 2566840318 EngsDesiredOperatingSpeed 1;
BA_ "SPN" SG_ 2566840318 EngsDesiredOperatingSpeed 515;
BA_ "SigType" SG_ 2566840318 NominalFrictionPercentTorque 1;
BA_ "SPN" SG_ 2566840318 NominalFrictionPercentTorque 514;
BA_ "SigType" SG_ 2364539902 ActMaxAvailEngPercentTorque 1;
BA_ "SPN" SG_ 2364539902 ActMaxAvailEngPercentTorque 3357;
BA_ "SigType" SG_ 2364539902 AccelPedalPos2 1;
BA_ "SPN" SG_ 2364539902 AccelPedalPos2 29;
BA_ "SigType" SG_ 2364539902 VhclAccelerationRateLimitStatus 4;
BA_ "SPN" SG_ 2364539902 VhclAccelerationRateLimitStatus 2979;
BA_ "SigType" SG_ 2364539902 EngPercentLoadAtCurrentSpeed 1.7E-308;
BA_ "SPN" SG_ 2364539902 EngPercentLoadAtCurrentSpeed 92;
BA_ "SigType" SG_ 2364539902 AccelPedal2LowIdleSwitch 4;
BA_ "SPN" SG_ 2364539902 AccelPedal2LowIdleSwitch 2970;
BA_ "SigType" SG_ 2364539902 RoadSpeedLimitStatus 4;
BA_ "SPN" SG_ 2364539902 RoadSpeedLimitStatus 1437;
BA_ "SigType" SG_ 2364539902 AccelPedalKickdownSwitch 4;
BA_ "SPN" SG_ 2364539902 AccelPedalKickdownSwitch 559;
BA_ "SigType" SG_ 2364539902 AccelPedal1LowIdleSwitch 4;
BA_ "SPN" SG_ 2364539902 AccelPedal1LowIdleSwitch 558;
BA_ "SigType" SG_ 2364539902 RemoteAccelPedalPos 1;
BA_ "SPN" SG_ 2364539902 RemoteAccelPedalPos 974;
BA_ "SigType" SG_ 2364539902 AccelPedalPos1 1;
BA_ "SPN" SG_ 2364539902 AccelPedalPos1 91;
BA_ "SigType" SG_ 2364540158 EngDemandPercentTorque 1;
BA_ "SPN" SG_ 2364540158 EngDemandPercentTorque 2432;
BA_ "SigType" SG_ 2364540158 EngStarterMode 4;
BA_ "SPN" SG_ 2364540158 EngStarterMode 1675;
BA_ "SigType" SG_ 2364540158 SrcAddrssOfCtrllngDvcForEngCtrl 1;
BA_ "SPN" SG_ 2364540158 SrcAddrssOfCtrllngDvcForEngCtrl 1483;
BA_ "SigType" SG_ 2364540158 EngSpeed 1.7E-308;
BA_ "SPN" SG_ 2364540158 EngSpeed 190;
BA_ "SigType" SG_ 2364540158 ActualEngPercentTorque 1;
BA_ "SPN" SG_ 2364540158 ActualEngPercentTorque 513;
BA_ "SigType" SG_ 2364540158 DriversDemandEngPercentTorque 1;
BA_ "SPN" SG_ 2364540158 DriversDemandEngPercentTorque 512;
BA_ "SigType" SG_ 2364540158 EngTorqueMode 1.7E-308;
BA_ "SPN" SG_ 2364540158 EngTorqueMode 899;
BA_ "SigType" SG_ 2566841342 SupportTSC1CtrlPurposeGroup4Of4 1;
BA_ "SPN" SG_ 2566841342 SupportTSC1CtrlPurposeGroup4Of4 3348;
BA_ "SigType" SG_ 2566841342 SupportVariableRateTSC1Message 1;
BA_ "SPN" SG_ 2566841342 SupportVariableRateTSC1Message 3344;
BA_ "SigType" SG_ 2566841342 SupportTSC1CtrlPurposeGroup3Of4 1;
BA_ "SPN" SG_ 2566841342 SupportTSC1CtrlPurposeGroup3Of4 3347;
BA_ "SigType" SG_ 2566841342 SupportTSC1CtrlPurposeGroup2Of4 1;
BA_ "SPN" SG_ 2566841342 SupportTSC1CtrlPurposeGroup2Of4 3346;
BA_ "SigType" SG_ 2566841342 SupportTSC1CtrlPurposeGroup1Of4 1;
BA_ "SPN" SG_ 2566841342 SupportTSC1CtrlPurposeGroup1Of4 3345;
BA_ "SigType" SG_ 2566841342 EngDefaultTorqueLimit 1;
BA_ "SPN" SG_ 2566841342 EngDefaultTorqueLimit 1846;
BA_ "SigType" SG_ 2566841342 EngMomentOfInertia 1;
BA_ "SPN" SG_ 2566841342 EngMomentOfInertia 1794;
BA_ "SigType" SG_ 2566841342 EngExRngRqdSpdCtrlRngUpperLimit 1;
BA_ "SPN" SG_ 2566841342 EngExRngRqdSpdCtrlRngUpperLimit 1712;
BA_ "SigType" SG_ 2566841342 EngRqdTorqueCtrlRangeUpperLimit 1;
BA_ "SPN" SG_ 2566841342 EngRqdTorqueCtrlRangeUpperLimit 538;
BA_ "SigType" SG_ 2566841342 EngRqdTorqueCtrlRangeLowerLimit 1;
BA_ "SPN" SG_ 2566841342 EngRqdTorqueCtrlRangeLowerLimit 537;
BA_ "SigType" SG_ 2566841342 EngRqedSpeedCtrlRangeUpperLimit 1;
BA_ "SPN" SG_ 2566841342 EngRqedSpeedCtrlRangeUpperLimit 536;
BA_ "SigType" SG_ 2566841342 EngRqedSpeedCtrlRangeLowerLimit 1;
BA_ "SPN" SG_ 2566841342 EngRqedSpeedCtrlRangeLowerLimit 535;
BA_ "SigType" SG_ 2566841342 EngMxMomentaryOverrideTimeLimit 1;
BA_ "SPN" SG_ 2566841342 EngMxMomentaryOverrideTimeLimit 534;
BA_ "SigType" SG_ 2566841342 EngMxMmntaryOverrideSpeedPoint7 1;
BA_ "SPN" SG_ 2566841342 EngMxMmntaryOverrideSpeedPoint7 533;
BA_ "SigType" SG_ 2566841342 EngReferenceTorque 1;
BA_ "SPN" SG_ 2566841342 EngReferenceTorque 544;
BA_ "SigType" SG_ 2566841342 EngSpeedAtHighIdlePoint6 1;
BA_ "SPN" SG_ 2566841342 EngSpeedAtHighIdlePoint6 532;
BA_ "SigType" SG_ 2566841342 EngGainOfEndspeedGovernor 1;
BA_ "SPN" SG_ 2566841342 EngGainOfEndspeedGovernor 545;
BA_ "SigType" SG_ 2566841342 EngPercentTorqueAtPoint5 1;
BA_ "SPN" SG_ 2566841342 EngPercentTorqueAtPoint5 543;
BA_ "SigType" SG_ 2566841342 EngSpeedAtPoint5 1;
BA_ "SPN" SG_ 2566841342 EngSpeedAtPoint5 531;
BA_ "SigType" SG_ 2566841342 EngPercentTorqueAtPoint4 1;
BA_ "SPN" SG_ 2566841342 EngPercentTorqueAtPoint4 542;
BA_ "SigType" SG_ 2566841342 EngSpeedAtPoint4 1;
BA_ "SPN" SG_ 2566841342 EngSpeedAtPoint4 530;
BA_ "SigType" SG_ 2566841342 EngPercentTorqueAtPoint3 1;
BA_ "SPN" SG_ 2566841342 EngPercentTorqueAtPoint3 541;
BA_ "SigType" SG_ 2566841342 EngSpeedAtPoint3 1;
BA_ "SPN" SG_ 2566841342 EngSpeedAtPoint3 529;
BA_ "SigType" SG_ 2566841342 EngPercentTorqueAtPoint2 1;
BA_ "SPN" SG_ 2566841342 EngPercentTorqueAtPoint2 540;
BA_ "SigType" SG_ 2566841342 EngSpeedAtPoint2 1;
BA_ "SPN" SG_ 2566841342 EngSpeedAtPoint2 528;
BA_ "SigType" SG_ 2566841342 EngPercentTorqueAtIdlePoint1 1;
BA_ "SPN" SG_ 2566841342 EngPercentTorqueAtIdlePoint1 539;
BA_ "SigType" SG_ 2566841342 EngSpeedAtIdlePoint1 1;
BA_ "SPN" SG_ 2566841342 EngSpeedAtIdlePoint1 188;
BA_ "SigType" SG_ 2566844926 EngShutdownOverrideSwitch 4;
BA_ "SPN" SG_ 2566844926 EngShutdownOverrideSwitch 1237;
BA_ "SigType" SG_ 2566844926 EngTestModeSwitch 4;
BA_ "SPN" SG_ 2566844926 EngTestModeSwitch 966;
BA_ "SigType" SG_ 2566844926 EngIdleDecrementSwitch 4;
BA_ "SPN" SG_ 2566844926 EngIdleDecrementSwitch 967;
BA_ "SigType" SG_ 2566844926 EngIdleIncrementSwitch 4;
BA_ "SPN" SG_ 2566844926 EngIdleIncrementSwitch 968;
BA_ "SigType" SG_ 2566844926 CruiseCtrlStates 4;
BA_ "SPN" SG_ 2566844926 CruiseCtrlStates 527;
BA_ "SigType" SG_ 2566844926 PTOState 4;
BA_ "SPN" SG_ 2566844926 PTOState 976;
BA_ "SigType" SG_ 2566844926 CruiseCtrlSetSpeed 1;
BA_ "SPN" SG_ 2566844926 CruiseCtrlSetSpeed 86;
BA_ "SigType" SG_ 2566844926 CruiseCtrlAccelerateSwitch 4;
BA_ "SPN" SG_ 2566844926 CruiseCtrlAccelerateSwitch 602;
BA_ "SigType" SG_ 2566844926 CruiseCtrlResumeSwitch 4;
BA_ "SPN" SG_ 2566844926 CruiseCtrlResumeSwitch 601;
BA_ "SigType" SG_ 2566844926 CruiseCtrlCoastSwitch 4;
BA_ "SPN" SG_ 2566844926 CruiseCtrlCoastSwitch 600;
BA_ "SigType" SG_ 2566844926 CruiseCtrlSetSwitch 4;
BA_ "SPN" SG_ 2566844926 CruiseCtrlSetSwitch 599;
BA_ "SigType" SG_ 2566844926 ClutchSwitch 4;
BA_ "SPN" SG_ 2566844926 ClutchSwitch 598;
BA_ "SigType" SG_ 2566844926 BrakeSwitch 4;
BA_ "SPN" SG_ 2566844926 BrakeSwitch 597;
BA_ "SigType" SG_ 2566844926 CruiseCtrlEnableSwitch 4;
BA_ "SPN" SG_ 2566844926 CruiseCtrlEnableSwitch 596;
BA_ "SigType" SG_ 2566844926 CruiseCtrlActive 4;
BA_ "SPN" SG_ 2566844926 CruiseCtrlActive 595;
BA_ "SigType" SG_ 2566844926 WheelBasedVehicleSpeed 1.7E-308;
BA_ "SPN" SG_ 2566844926 WheelBasedVehicleSpeed 84;
BA_ "SigType" SG_ 2566844926 CruiseCtrlPauseSwitch 4;
BA_ "SPN" SG_ 2566844926 CruiseCtrlPauseSwitch 1633;
BA_ "SigType" SG_ 2566844926 ParkingBrakeSwitch 4;
BA_ "SPN" SG_ 2566844926 ParkingBrakeSwitch 70;
BA_ "SigType" SG_ 2566844926 TwoSpeedAxleSwitch 4;
BA_ "SPN" SG_ 2566844926 TwoSpeedAxleSwitch 69;
BA_ "SigType" SG_ 2566845950 RoadSurfaceTemp 1;
BA_ "SPN" SG_ 2566845950 RoadSurfaceTemp 79;
BA_ "SigType" SG_ 2566845950 EngAirInletTemp 1;
BA_ "SPN" SG_ 2566845950 EngAirInletTemp 172;
BA_ "SigType" SG_ 2566845950 AmbientAirTemp 1;
BA_ "SPN" SG_ 2566845950 AmbientAirTemp 171;
BA_ "SigType" SG_ 2566845950 CabInteriorTemp 1;
BA_ "SPN" SG_ 2566845950 CabInteriorTemp 170;
BA_ "SigType" SG_ 2566845950 BarometricPress 1;
BA_ "SPN" SG_ 2566845950 BarometricPress 108;
BA_ "SPN" SG_ 2562981630 IndividualDTCClearControlByte 3034;
BA_ "SPN" SG_ 2562981630 CtrlByteIndicIndividualDTCClear 3035;
BA_ "SPN" SG_ 2562981630 SPN1 1214;
BA_ "SPN" SG_ 2562981630 SPN1High 1214;
BA_ "SPN" SG_ 2562981630 FailureModeIdentifier1 1215;
BA_ "SigType" SG_ 2348875518 EngineRequestedTorqueHiRes 1;
BA_ "SPN" SG_ 2348875518 EngineRequestedTorqueHiRes 4191;
BA_ "SPN" SG_ 2348875518 ControlPurpose 3350;
BA_ "SigType" SG_ 2348875518 ControlPurpose 4;
BA_ "SPN" SG_ 2348875518 TransmissionRate 3349;
BA_ "SigType" SG_ 2348875518 TransmissionRate 4;
BA_ "SPN" SG_ 2348875518 EngRqedTorque_TorqueLimit 518;
BA_ "SigType" SG_ 2348875518 EngRqedTorque_TorqueLimit 1;
BA_ "SPN" SG_ 2348875518 EngRqedSpeed_SpeedLimit 898;
BA_ "SigType" SG_ 2348875518 EngRqedSpeed_SpeedLimit 1;
BA_ "SPN" SG_ 2348875518 OverrideCtrlModePriority 897;
BA_ "SigType" SG_ 2348875518 OverrideCtrlModePriority 4;
BA_ "SPN" SG_ 2348875518 EngRqedSpeedCtrlConditions 696;
BA_ "SigType" SG_ 2348875518 EngRqedSpeedCtrlConditions 4;
BA_ "SPN" SG_ 2348875518 EngOverrideCtrlMode 695;
BA_ "SigType" SG_ 2348875518 EngOverrideCtrlMode 4;
BA_ "SigType" SG_ 2566845952 EngCoolantFilterDiffPress 1;
BA_ "SPN" SG_ 2566845952 EngCoolantFilterDiffPress 112;
BA_ "SigType" SG_ 2566845952 EngExhaustGasTemp 1;
BA_ "SPN" SG_ 2566845952 EngExhaustGasTemp 173;
BA_ "SigType" SG_ 2566845952 EngAirFilter1DiffPress 1;
BA_ "SPN" SG_ 2566845952 EngAirFilter1DiffPress 107;
BA_ "SigType" SG_ 2566845952 EngAirInletPress 1;
BA_ "SPN" SG_ 2566845952 EngAirInletPress 106;
BA_ "SigType" SG_ 2566845952 EngIntakeManifold1Temp 1;
BA_ "SPN" SG_ 2566845952 EngIntakeManifold1Temp 105;
BA_ "SigType" SG_ 2566845952 EngTurboBoostPress 1.7E-308;
BA_ "SPN" SG_ 2566845952 EngTurboBoostPress 102;
BA_ "SigType" SG_ 2566845952 EngParticulateTrapInletPress 1;
BA_ "SPN" SG_ 2566845952 EngParticulateTrapInletPress 81;
BA_ "SigType" SG_ 2566841600 EngTotalRevolutions 1;
BA_ "SPN" SG_ 2566841600 EngTotalRevolutions 249;
BA_ "SigType" SG_ 2566841600 EngTotalHoursOfOperation 1;
BA_ "SPN" SG_ 2566841600 EngTotalHoursOfOperation 247;
BA_ "SigType" SG_ 2566832384 HighResolutionTripDistance 1;
BA_ "SPN" SG_ 2566832384 HighResolutionTripDistance 918;
BA_ "SigType" SG_ 2566832384 HghRslutionTotalVehicleDistance 1;
BA_ "SPN" SG_ 2566832384 HghRslutionTotalVehicleDistance 917;
BA_ "SigType" SG_ 2566840320 TotalVehicleDistance 1;
BA_ "SPN" SG_ 2566840320 TotalVehicleDistance 245;
BA_ "SigType" SG_ 2566840320 TripDistance 1;
BA_ "SPN" SG_ 2566840320 TripDistance 244;
BA_ "SigType" SG_ 2566839552 EngTurboOilLevelSwitch 4;
BA_ "SPN" SG_ 2566839552 EngTurboOilLevelSwitch 1665;
BA_ "SigType" SG_ 2566839552 EngTurbo1Speed 1;
BA_ "SPN" SG_ 2566839552 EngTurbo1Speed 103;
BA_ "SigType" SG_ 2566839552 EngTurboLubeOilPress1 1;
BA_ "SPN" SG_ 2566839552 EngTurboLubeOilPress1 104;
BA_ "SigType" SG_ 2566839038 SoftwareID3 8;
BA_ "SPN" SG_ 2566839038 SoftwareID3 234;
BA_ "SigType" SG_ 2566839038 SoftwareID2 8;
BA_ "SPN" SG_ 2566839038 SoftwareID2 234;
BA_ "SigType" SG_ 2566839038 SoftwareID1 8;
BA_ "SPN" SG_ 2566839038 SoftwareID1 234;
BA_ "SigType" SG_ 2566839038 NmbrOfSftwrIdentificationFields 1;
BA_ "SPN" SG_ 2566839038 NmbrOfSftwrIdentificationFields 965;
BA_ "SigType" SG_ 2566841344 EngOverspeedTest 4;
BA_ "SPN" SG_ 2566841344 EngOverspeedTest 2812;
BA_ "SigType" SG_ 2566841344 EngAirShutoffCmdStatus 4;
BA_ "SPN" SG_ 2566841344 EngAirShutoffCmdStatus 2813;
BA_ "SigType" SG_ 2566841344 EngAlarmOutputCmdStatus 4;
BA_ "SPN" SG_ 2566841344 EngAlarmOutputCmdStatus 2814;
BA_ "SigType" SG_ 2566841344 EngAlarmAcknowledge 4;
BA_ "SPN" SG_ 2566841344 EngAlarmAcknowledge 2815;
BA_ "SigType" SG_ 2566841344 EngProtectionSystemConfig 4;
BA_ "SPN" SG_ 2566841344 EngProtectionSystemConfig 1111;
BA_ "SigType" SG_ 2566841344 EngProtectionSystemTimerState 4;
BA_ "SPN" SG_ 2566841344 EngProtectionSystemTimerState 1107;
BA_ "SigType" SG_ 2566841344 EngPrtectionSystemTimerOverride 4;
BA_ "SPN" SG_ 2566841344 EngPrtectionSystemTimerOverride 1108;
BA_ "SigType" SG_ 2566841344 EngPrtctnSystmApprchingShutdown 4;
BA_ "SPN" SG_ 2566841344 EngPrtctnSystmApprchingShutdown 1109;
BA_ "SigType" SG_ 2566841344 EngPrtctionSystemHasShutdownEng 4;
BA_ "SPN" SG_ 2566841344 EngPrtctionSystemHasShutdownEng 1110;
BA_ "SigType" SG_ 2566841344 EngWaitToStartLamp 4;
BA_ "SPN" SG_ 2566841344 EngWaitToStartLamp 1081;
BA_ "SigType" SG_ 2566841344 RefrigerantHighPressSwitch 4;
BA_ "SPN" SG_ 2566841344 RefrigerantHighPressSwitch 605;
BA_ "SigType" SG_ 2566841344 RefrigerantLowPressSwitch 4;
BA_ "SPN" SG_ 2566841344 RefrigerantLowPressSwitch 875;
BA_ "SigType" SG_ 2566841344 A_CHighPressFanSwitch 4;
BA_ "SPN" SG_ 2566841344 A_CHighPressFanSwitch 985;
BA_ "SigType" SG_ 2566841344 EngIdleShutdownTimerFunction 4;
BA_ "SPN" SG_ 2566841344 EngIdleShutdownTimerFunction 591;
BA_ "SigType" SG_ 2566841344 EngIdleShutdownTimerState 4;
BA_ "SPN" SG_ 2566841344 EngIdleShutdownTimerState 590;
BA_ "SigType" SG_ 2566841344 EngIdleShutdownTimerOverride 4;
BA_ "SPN" SG_ 2566841344 EngIdleShutdownTimerOverride 592;
BA_ "SigType" SG_ 2566841344 EngIdleShutdownDriverAlertMode 4;
BA_ "SPN" SG_ 2566841344 EngIdleShutdownDriverAlertMode 594;
BA_ "SigType" SG_ 2566841344 EngIdleShutdownHasShutdownEng 4;
BA_ "SPN" SG_ 2566841344 EngIdleShutdownHasShutdownEng 593;
BA_ "SigType" SG_ 2566844416 OperatorPTOMemorySelectSwitch 4;
BA_ "SPN" SG_ 2566844416 OperatorPTOMemorySelectSwitch 2897;
BA_ "SigType" SG_ 2566844416 EngPTOAccelerateSwitch 4;
BA_ "SPN" SG_ 2566844416 EngPTOAccelerateSwitch 981;
BA_ "SigType" SG_ 2566844416 EngPTOResumeSwitch 4;
BA_ "SPN" SG_ 2566844416 EngPTOResumeSwitch 982;
BA_ "SigType" SG_ 2566844416 EngPTOCoast_DecelerateSwitch 4;
BA_ "SPN" SG_ 2566844416 EngPTOCoast_DecelerateSwitch 983;
BA_ "SigType" SG_ 2566844416 EngPTOSetSwitch 4;
BA_ "SPN" SG_ 2566844416 EngPTOSetSwitch 984;
BA_ "SigType" SG_ 2566844416 EngRmtPTOVriableSpeedCtrlSwitch 4;
BA_ "SPN" SG_ 2566844416 EngRmtPTOVriableSpeedCtrlSwitch 978;
BA_ "SigType" SG_ 2566844416 EngRmtPTOPrprgrmmdSpdCtrlSwitch 4;
BA_ "SPN" SG_ 2566844416 EngRmtPTOPrprgrmmdSpdCtrlSwitch 979;
BA_ "SigType" SG_ 2566844416 EngPTOEnableSwitch 4;
BA_ "SPN" SG_ 2566844416 EngPTOEnableSwitch 980;
BA_ "SigType" SG_ 2566844416 PowerTakeoffSetSpeed 1;
BA_ "SPN" SG_ 2566844416 PowerTakeoffSetSpeed 187;
BA_ "SigType" SG_ 2566844416 PowerTakeoffSpeed 1;
BA_ "SPN" SG_ 2566844416 PowerTakeoffSpeed 186;
BA_ "SigType" SG_ 2566844416 PowerTakeoffOilTemp 1;
BA_ "SPN" SG_ 2566844416 PowerTakeoffOilTemp 90;
BA_ "SigType" SG_ 2566844416 RmtPTOPrprgrmmdSpeedCtrlSwitch2 4;
BA_ "SPN" SG_ 2566844416 RmtPTOPrprgrmmdSpeedCtrlSwitch2 3447;
BA_ "SigType" SG_ 2566844416 AuxInputIgnoreSwitch 4;
BA_ "SPN" SG_ 2566844416 AuxInputIgnoreSwitch 3448;
BA_ "SigType" SG_ 2566844928 EngAverageFuelEconomy 1;
BA_ "SPN" SG_ 2566844928 EngAverageFuelEconomy 185;
BA_ "SigType" SG_ 2566844928 EngInstantaneousFuelEconomy 1;
BA_ "SPN" SG_ 2566844928 EngInstantaneousFuelEconomy 184;
BA_ "SigType" SG_ 2566844928 EngFuelRate 1;
BA_ "SPN" SG_ 2566844928 EngFuelRate 183;
BA_ "SigType" SG_ 2566844928 EngThrottlePos 1;
BA_ "SPN" SG_ 2566844928 EngThrottlePos 51;
BA_ "SigType" SG_ 2566842624 EngTotalFuelUsed 1;
BA_ "SPN" SG_ 2566842624 EngTotalFuelUsed 250;
BA_ "SigType" SG_ 2566842624 EngTripFuel 1;
BA_ "SPN" SG_ 2566842624 EngTripFuel 182;
BA_ "SigType" SG_ 2566831360 FanSpeed 1;
BA_ "SPN" SG_ 2566831360 FanSpeed 1639;
BA_ "SigType" SG_ 2566831360 FanDriveState 4;
BA_ "SPN" SG_ 2566831360 FanDriveState 977;
BA_ "SigType" SG_ 2566831360 EstPercentFanSpeed 1;
BA_ "SPN" SG_ 2566831360 EstPercentFanSpeed 975;
VAL_ 3221225472 FlashRedStopLamp 3 "Unavailable / Do Not Flash" 2 "Reserved" 1 "Fast Flash" 0 "Slow Flash" ;
VAL_ 3221225472 FlashProtectLamp 3 "Unavailable / Do Not Flash" 2 "Reserved" 1 "Fast Flash" 0 "Slow Flash" ;
VAL_ 3221225472 FlashMalfuncIndicatorLamp 3 "Unavailable / Do Not Flash" 2 "Reserved" 1 "Fast Flash" 0 "Slow Flash" ;
VAL_ 3221225472 FlashAmberWarningLamp 3 "Unavailable / Do Not Flash" 2 "Reserved" 1 "Fast Flash" 0 "Slow Flash" ;
VAL_ 3221225472 MalfunctionIndicatorLampStatus 3 "Not available" 2 "Reserved" 1 "Lamp on" 0 "Lamp off" ;
VAL_ 3221225472 RedStopLampState 3 "Not available" 2 "Reserved" 1 "Lamp on" 0 "Lamp off" ;
VAL_ 3221225472 AmberWarningLampStatus 3 "Not available" 2 "Reserved" 1 "Lamp on" 0 "Lamp off" ;
VAL_ 3221225472 ProtectLampStatus 3 "Not available" 2 "Reserved" 1 "Lamp on" 0 "Lamp off" ;
VAL_ 2566841598 EngOverspeedTest 3 "NotAvailable" 2 "Reserved" 1 "EngOverspeedTestActive" 0 "EngOverspeedTestNotActive" ;
VAL_ 2566841598 EngAirShutoffCmdStatus 0 "ArShtffDsbldNtAttmptngTShtffEng" 3 "NotAvailable" 2 "Reserved" 1 "ArShtffEnbldAttmptngTShtffEngAr" ;
VAL_ 2566841598 EngAlarmOutputCmdStatus 3 "NotAvailable" 2 "Reserved" 1 "EngAlarmOutputCmdActive" 0 "EngAlarmOutputCmdNotActive" ;
VAL_ 2566841598 EngAlarmAcknowledge 3 "NotAvailable" 2 "Error" 1 "EngAlarmAcknowledgeActive" 0 "EngAlarmAcknowledgeNotActive" ;
VAL_ 2566841598 EngProtectionSystemConfig 3 "NotAvailable" 2 "Error" 1 "EnabledInCalib" 0 "DisabledInCalib" ;
VAL_ 2566841598 EngProtectionSystemTimerState 3 "NotAvailable" 2 "Error" 1 "Active" 0 "Inactive" ;
VAL_ 2566841598 EngPrtectionSystemTimerOverride 3 "NotAvailable" 2 "Error" 1 "Active" 0 "Inactive" ;
VAL_ 2566841598 EngPrtctnSystmApprchingShutdown 3 "NotAvailable" 2 "Error" 1 "Approaching" 0 "NotApproaching" ;
VAL_ 2566841598 EngPrtctionSystemHasShutdownEng 0 "No" ;
VAL_ 2566841598 EngWaitToStartLamp 3 "NotAvailable" 2 "Error" 1 "On" 0 "Off" ;
VAL_ 2566841598 RefrigerantHighPressSwitch 3 "NotAvailable" 2 "Error" 1 "PrssTHghCmprssrCltchMyBDsngaged" 0 "PressNormal" ;
VAL_ 2566841598 RefrigerantLowPressSwitch 3 "NotAvailable" 2 "Error" 1 "PrssTLwCmprssrCltchMyBDsengaged" 0 "PressNormal" ;
VAL_ 2566841598 A_CHighPressFanSwitch 3 "NotAvailable" 2 "Error" 1 "PressHighFanMayBeEngaged" 0 "PressNormal" ;
VAL_ 2566841598 EngIdleShutdownTimerFunction 3 "NotAvailable" 2 "Error" 1 "EnabledInCalib" 0 "DisabledInCalib" ;
VAL_ 2566841598 EngIdleShutdownTimerState 3 "NotAvailable" 2 "Error" 1 "Active" 0 "Inactive" ;
VAL_ 2566841598 EngIdleShutdownTimerOverride 3 "NotAvailable" 2 "Error" 1 "Active" 0 "Inactive" ;
VAL_ 2566841598 EngIdleShutdownDriverAlertMode 3 "NotAvailable" 2 "Error" 1 "Active" 0 "Inactive" ;
VAL_ 2566841598 EngIdleShutdownHasShutdownEng 1 "Yes" 0 "No" ;
VAL_ 2566844670 OperatorPTOMemorySelectSwitch 3 "notAvailable" 2 "error" 1 "PTOSetSpeedMemory2Selected" 0 "PTOSetSpeedMemory1Selected" ;
VAL_ 2566844670 EngPTOAccelerateSwitch 3 "NotAvailable" 2 "Error" 1 "On" 0 "Off" ;
VAL_ 2566844670 EngPTOResumeSwitch 3 "NotAvailable" 2 "Error" 1 "On" 0 "Off" ;
VAL_ 2566844670 EngPTOCoast_DecelerateSwitch 3 "NotAvailable" 2 "Error" 1 "On" 0 "Off" ;
VAL_ 2566844670 EngPTOSetSwitch 3 "NotAvailable" 2 "Error" 1 "On" 0 "Off" ;
VAL_ 2566844670 EngRmtPTOVriableSpeedCtrlSwitch 3 "NotAvailable" 2 "Error" 1 "On" 0 "Off" ;
VAL_ 2566844670 EngRmtPTOPrprgrmmdSpdCtrlSwitch 3 "NotAvailable" 2 "Error" 1 "On" 0 "Off" ;
VAL_ 2566844670 EngPTOEnableSwitch 3 "NotAvailable" 2 "Error" 1 "On" 0 "Off" ;
VAL_ 2566844670 RmtPTOPrprgrmmdSpeedCtrlSwitch2 3 "NotAvailable" 2 "Error" 1 "On" 0 "Off" ;
VAL_ 2566844670 AuxInputIgnoreSwitch 3 "NotAvailable" 2 "Error" 1 "On" 0 "Off" ;
VAL_ 2566831614 FanDriveState 15 "NotAvailable" 14 "Other" 13 "EngBrake" 12 "Timer" 11 "A_CSystem" 10 "TransRetarder" 9 "ManualCtrl" 8 "NotDefined" 7 "DefaultOperation" 6 "ExcessiveHydOilTemp" 5 "ExcessiveTransOilTemp" 4 "ExcessiveEngCoolantTemp" 3 "ExcessiveEngOilTemp" 2 "ExcessiveEngAirTemp" 1 "EngSystemGeneral" 0 "FanOff" ;
VAL_ 2633935358 EngExhstGsOxygnSnsrClsdLpOprton 3 "DontCare_TakeNoAction" 2 "Reserved" 1 "CmdToEnableFunction" 0 "CmdToDisableFunction" ;
VAL_ 2364539902 VhclAccelerationRateLimitStatus 3 "NotAvailable" 2 "Reserved" 1 "LimitActive" 0 "LimitNotActive" ;
VAL_ 2364539902 AccelPedal2LowIdleSwitch 3 "NotAvailable" 2 "Error" 1 "AccelPedal2InLowIdleCondition" 0 "AcclPedal2NotInLowIdleCondition" ;
VAL_ 2364539902 RoadSpeedLimitStatus 3 "NotAvailable" 2 "Error" 1 "NotActive" 0 "Active" ;
VAL_ 2364539902 AccelPedalKickdownSwitch 3 "NotAvailable" 2 "Error" 1 "KickdownActive" 0 "KickdownPassive" ;
VAL_ 2364539902 AccelPedal1LowIdleSwitch 3 "NotAvailable" 2 "Error" 1 "AccelPedal1InLowIdleCondition" 0 "AcclPedal1NotInLowIdleCondition" ;
VAL_ 2364540158 EngStarterMode 15 "notAvailable" 14 "error" 12 "starterInhibitedReasonUnknown" 9 "1011Reserved" 8 "strtrInhbtdDueToStarterOvertemp" 7 "strtrInhbtdDToActiveImmobilizer" 6 "strtrInhbtdDTDrvlnEnggdOthrTrns" 5 "strtrInhbtdDTEngNtReadyForStart" 4 "strtrInhbtdDToEngAlreadyRunning" 3 "strtFnshdStrtrNtActvAftrHvngBnA" 2 "starterActiveGearEngaged" 1 "starterActiveGearNotEngaged" 0 "startNotRqed" ;
VAL_ 2364540158 EngTorqueMode 15 "Not available" 11 "Remote accelerator" 10 "Braking system" 9 "High speed governor" 8 "Torque limiting" 7 "ABS control" 6 "Transmission control" 5 "ASR control" 4 "Road speed governor" 3 "PTO governor" 2 "Cruise control" 1 "Accelerator pedal/operator selec" 0 "Low idle governor/no request (de" ;
VAL_ 2566841342 SupportTSC1CtrlPurposeGroup4Of4 1 "P25ReservedForAssignmentBySAE" ;
VAL_ 2566841342 SupportVariableRateTSC1Message 1 "MsTransRate" ;
VAL_ 2566841342 SupportTSC1CtrlPurposeGroup3Of4 1 "P17ReservedForAssignmentBySAE" ;
VAL_ 2566841342 SupportTSC1CtrlPurposeGroup2Of4 1 "P9ReservedForAssignmentBySAE" ;
VAL_ 2566841342 SupportTSC1CtrlPurposeGroup1Of4 1 "P1AccelPedal_OperatorSelection" ;
VAL_ 2566844926 EngShutdownOverrideSwitch 3 "NotAvailable" 2 "Error" 1 "On" 0 "Off" ;
VAL_ 2566844926 EngTestModeSwitch 3 "NotAvailable" 2 "Error" 1 "On" 0 "Off" ;
VAL_ 2566844926 EngIdleDecrementSwitch 3 "NotAvailable" 2 "Error" 1 "On" 0 "Off" ;
VAL_ 2566844926 EngIdleIncrementSwitch 3 "NotAvailable" 2 "Error" 1 "On" 0 "Off" ;
VAL_ 2566844926 PTOState 31 "NotAvailable" 20 "11110NotDefined" 19 "PTOSetSpeedMemory2" 18 "PTOSetSpeedMemory1" 17 "PreprogrammedSetSpeed8" 16 "PreprogrammedSetSpeed7" 15 "PreprogrammedSetSpeed6" 14 "PreprogrammedSetSpeed5" 13 "PreprogrammedSetSpeed4" 12 "PreprogrammedSetSpeed3" 11 "PreprogrammedSetSpeed2" 10 "PreprogrammedSetSpeed1" 9 "AccelOverride" 8 "Accelerate" 7 "Resume" 6 "Decelerate_Coast" 5 "Set" 4 "RemoteStandby" 3 "Standby" 2 "RemoteHold" 1 "Hold" 0 "Off_Disabled" ;
VAL_ 2566844926 CruiseCtrlAccelerateSwitch 3 "NotAvailable" 2 "Error" 1 "CrsCtrlActivatorInPosAccelerate" 0 "CrsCtrlActvtrNotInPosAccelerate" ;
VAL_ 2566844926 CruiseCtrlResumeSwitch 3 "NotAvailable" 2 "Error" 1 "CruiseCtrlActivatorInPosResume" 0 "CrseCtrlActivatorNotInPosResume" ;
VAL_ 2566844926 CruiseCtrlCoastSwitch 3 "NotAvailable" 2 "Error" 1 "CruiseCtrlActivatorInPosCoast" 0 "CriseCtrlActivatorNotInPosCoast" ;
VAL_ 2566844926 CruiseCtrlSetSwitch 3 "NotAvailable" 2 "Error" 1 "CruiseCtrlActivatorInPosSet" 0 "CruiseCtrlActivatorNotInPosSet" ;
VAL_ 2566844926 ClutchSwitch 3 "NotAvailable" 2 "Error" 1 "ClutchPedalDepressed" 0 "ClutchPedalReleased" ;
VAL_ 2566844926 BrakeSwitch 3 "NotAvailable" 2 "Error" 1 "BrakePedalDepressed" 0 "BrakePedalReleased" ;
VAL_ 2566844926 CruiseCtrlEnableSwitch 3 "NotAvailable" 2 "Error" 1 "CruiseCtrlEnabled" 0 "CruiseCtrlDisabled" ;
VAL_ 2566844926 CruiseCtrlActive 3 "NotAvailable" 2 "Error" 1 "CruiseCtrlSwitchedOn" 0 "CruiseCtrlSwitchedOff" ;
VAL_ 2566844926 CruiseCtrlPauseSwitch 3 "TakeNoAction" 2 "ErrorIndicator" 1 "On" 0 "Off" ;
VAL_ 2566844926 ParkingBrakeSwitch 3 "NotAvailable" 2 "Error" 1 "ParkingBrakeSet" 0 "ParkingBrakeNotSet" ;
VAL_ 2566844926 TwoSpeedAxleSwitch 3 "NotAvailable" 2 "Error" 1 "HighSpeedRange" 0 "LowSpeedRange" ;
VAL_ 2348875518 ControlPurpose 5 "TemporaryPowerTrainControl" 4 "EngineProtection" 3 "RoadSpeedGovernor" 2 "PTOGovernor" 1 "CruiseControl" 0 "AcceleratorPedal" ;
VAL_ 2348875518 TransmissionRate 7 "UseStandardRate" 6 "25ms" 5 "50ms" 4 "100ms" 3 "250ms" 2 "500ms" 1 "750ms" 0 "1000ms" ;
VAL_ 2348875518 OverrideCtrlModePriority 3 "LowPriority" 2 "MdmPrrtyUsdFrPwrtrnCtrlOprtnsWh" 1 "HighPriority" 0 "HghstPrrtyUsdFrSttnsThtRqrImmdt" ;
VAL_ 2348875518 EngRqedSpeedCtrlConditions 2 "ThsCtrlCndtnHsBnOptmzdTMnmzRpmO" 3 "StbltyOptmzdFrDrvlnEnggdAnd_OrI" 1 "StbltyOptmzdFrDrvlnDsnggdAndNnl" 0 "ThsSpdGvrnrGnSlctnIsAdjstdTPrvd" ;
VAL_ 2348875518 EngOverrideCtrlMode 3 "Spd_TrqLmtCtrlLmtSpdAnd_OrTrqBs" 2 "TrqCtrlCntrlTrqTInclddDsrdTrqVl" 1 "SpdCtrlGvrnSpdTInclddDsrdSpdVle" 0 "OvrrdDsbldDsblAnyExstngCtrlCmdd" ;
VAL_ 2566841344 EngOverspeedTest 3 "NotAvailable" 2 "Reserved" 1 "EngOverspeedTestActive" 0 "EngOverspeedTestNotActive" ;
VAL_ 2566841344 EngAirShutoffCmdStatus 0 "ArShtffDsbldNtAttmptngTShtffEng" 3 "NotAvailable" 2 "Reserved" 1 "ArShtffEnbldAttmptngTShtffEngAr" ;
VAL_ 2566841344 EngAlarmOutputCmdStatus 3 "NotAvailable" 2 "Reserved" 1 "EngAlarmOutputCmdActive" 0 "EngAlarmOutputCmdNotActive" ;
VAL_ 2566841344 EngAlarmAcknowledge 3 "NotAvailable" 2 "Error" 1 "EngAlarmAcknowledgeActive" 0 "EngAlarmAcknowledgeNotActive" ;
VAL_ 2566841344 EngProtectionSystemConfig 3 "NotAvailable" 2 "Error" 1 "EnabledInCalib" 0 "DisabledInCalib" ;
VAL_ 2566841344 EngProtectionSystemTimerState 3 "NotAvailable" 2 "Error" 1 "Active" 0 "Inactive" ;
VAL_ 2566841344 EngPrtectionSystemTimerOverride 3 "NotAvailable" 2 "Error" 1 "Active" 0 "Inactive" ;
VAL_ 2566841344 EngPrtctnSystmApprchingShutdown 3 "NotAvailable" 2 "Error" 1 "Approaching" 0 "NotApproaching" ;
VAL_ 2566841344 EngPrtctionSystemHasShutdownEng 0 "No" ;
VAL_ 2566841344 EngWaitToStartLamp 3 "NotAvailable" 2 "Error" 1 "On" 0 "Off" ;
VAL_ 2566841344 RefrigerantHighPressSwitch 3 "NotAvailable" 2 "Error" 1 "PrssTHghCmprssrCltchMyBDsngaged" 0 "PressNormal" ;
VAL_ 2566841344 RefrigerantLowPressSwitch 3 "NotAvailable" 2 "Error" 1 "PrssTLwCmprssrCltchMyBDsengaged" 0 "PressNormal" ;
VAL_ 2566841344 A_CHighPressFanSwitch 3 "NotAvailable" 2 "Error" 1 "PressHighFanMayBeEngaged" 0 "PressNormal" ;
VAL_ 2566841344 EngIdleShutdownTimerFunction 3 "NotAvailable" 2 "Error" 1 "EnabledInCalib" 0 "DisabledInCalib" ;
VAL_ 2566841344 EngIdleShutdownTimerState 3 "NotAvailable" 2 "Error" 1 "Active" 0 "Inactive" ;
VAL_ 2566841344 EngIdleShutdownTimerOverride 3 "NotAvailable" 2 "Error" 1 "Active" 0 "Inactive" ;
VAL_ 2566841344 EngIdleShutdownDriverAlertMode 3 "NotAvailable" 2 "Error" 1 "Active" 0 "Inactive" ;
VAL_ 2566841344 EngIdleShutdownHasShutdownEng 1 "Yes" 0 "No" ;
VAL_ 2566844416 OperatorPTOMemorySelectSwitch 3 "notAvailable" 2 "error" 1 "PTOSetSpeedMemory2Selected" 0 "PTOSetSpeedMemory1Selected" ;
VAL_ 2566844416 EngPTOAccelerateSwitch 3 "NotAvailable" 2 "Error" 1 "On" 0 "Off" ;
VAL_ 2566844416 EngPTOResumeSwitch 3 "NotAvailable" 2 "Error" 1 "On" 0 "Off" ;
VAL_ 2566844416 EngPTOCoast_DecelerateSwitch 3 "NotAvailable" 2 "Error" 1 "On" 0 "Off" ;
VAL_ 2566844416 EngPTOSetSwitch 3 "NotAvailable" 2 "Error" 1 "On" 0 "Off" ;
VAL_ 2566844416 EngRmtPTOVriableSpeedCtrlSwitch 3 "NotAvailable" 2 "Error" 1 "On" 0 "Off" ;
VAL_ 2566844416 EngRmtPTOPrprgrmmdSpdCtrlSwitch 3 "NotAvailable" 2 "Error" 1 "On" 0 "Off" ;
VAL_ 2566844416 EngPTOEnableSwitch 3 "NotAvailable" 2 "Error" 1 "On" 0 "Off" ;
VAL_ 2566844416 RmtPTOPrprgrmmdSpeedCtrlSwitch2 3 "NotAvailable" 2 "Error" 1 "On" 0 "Off" ;
VAL_ 2566844416 AuxInputIgnoreSwitch 3 "NotAvailable" 2 "Error" 1 "On" 0 "Off" ;
VAL_ 2566831360 FanDriveState 15 "NotAvailable" 14 "Other" 13 "EngBrake" 12 "Timer" 11 "A_CSystem" 10 "TransRetarder" 9 "ManualCtrl" 8 "NotDefined" 7 "DefaultOperation" 6 "ExcessiveHydOilTemp" 5 "ExcessiveTransOilTemp" 4 "ExcessiveEngCoolantTemp" 3 "ExcessiveEngOilTemp" 2 "ExcessiveEngAirTemp" 1 "EngSystemGeneral" 0 "FanOff" ;
